VERSION ""

NS_ :

BS_:

BU_: BMS CanAnalyzer Charger ANY BMS CanAnalyzer Charger ANY

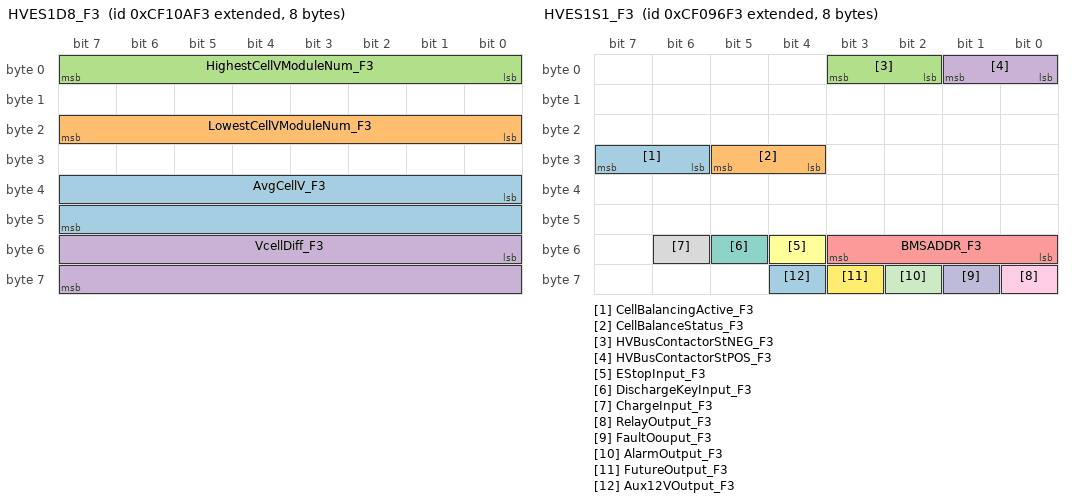
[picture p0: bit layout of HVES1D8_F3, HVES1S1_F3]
BO_ 2364607219 HVES1D8_F3: 8 BMS
 SG_ AvgCellV_F3 : 32|16@1+ (0.001,0) [0|65.535] "V"  CanAnalyzer
 SG_ LowestCellVModuleNum_F3 : 16|8@1+ (1,0) [0|250] ""  CanAnalyzer
 SG_ HighestCellVModuleNum_F3 : 0|8@1+ (1,0) [0|250] ""  CanAnalyzer
 SG_ VcellDiff_F3 : 48|16@1+ (0.001,0) [0|65.535] "V" Vector__XXX

BO_ 2364577523 HVES1S1_F3: 8 BMS
 SG_ CellBalancingActive_F3 : 30|2@1+ (1,0) [0|3] ""  CanAnalyzer
 SG_ CellBalanceStatus_F3 : 28|2@1+ (1,0) [0|3] ""  CanAnalyzer
 SG_ HVBusContactorStNEG_F3 : 2|2@1+ (1,0) [0|3] ""  CanAnalyzer
 SG_ HVBusContactorStPOS_F3 : 0|2@1+ (1,0) [0|3] ""  CanAnalyzer
 SG_ BMSADDR_F3 : 48|4@1+ (1,0) [0|1] "" Vector__XXX
 SG_ EStopInput_F3 : 52|1@1+ (1,0) [0|1] "" Vector__XXX
 SG_ DischargeKeyInput_F3 : 53|1@1+ (1,0) [0|1] "" Vector__XXX
 SG_ ChargeInput_F3 : 54|1@1+ (1,0) [0|1] "" Vector__XXX
 SG_ RelayOutput_F3 : 56|1@1+ (1,0) [0|1] "" Vector__XXX
 SG_ FaultOouput_F3 : 57|1@1+ (1,0) [0|1] "" Vector__XXX
 SG_ AlarmOutput_F3 : 58|1@1+ (1,0) [0|1] "" Vector__XXX
 SG_ FutureOutput_F3 : 59|1@1+ (1,0) [0|1] "" Vector__XXX
 SG_ Aux12VOutput_F3 : 60|1@1+ (1,0) [0|1] "" Vector__XXX

BO_ 2364577267 HVES1D6_F3: 8 BMS
 SG_ BusVoltage_F3 : 0|16@1+ (0.05,0) [0|65.535] "V"  CanAnalyzer

BO_ 2364576755 HVES1D4_F3: 8 BMS
 SG_ ChargeCapacity_01 : 16|16@1+ (0.01,0) [0|655.35] "Ah"  CanAnalyzer
 SG_ DischargeCapacity_01 : 0|16@1+ (0.01,0) [0|655.35] "Ah"  CanAnalyzer
 SG_ AvailableCapacity_01 : 48|16@1+ (0.01,0) [0|655.35] "Ah" Vector__XXX

BO_ 2350641993 HVES1C1_CF3: 8 ANY
 SG_ HVBusConnectCmd_cF3 : 0|2@1+ (1,0) [0|3] ""  CanAnalyzer
 SG_ BMSAddr_cF3 : 24|8@1+ (1,0) [101|114] "" Vector__XXX

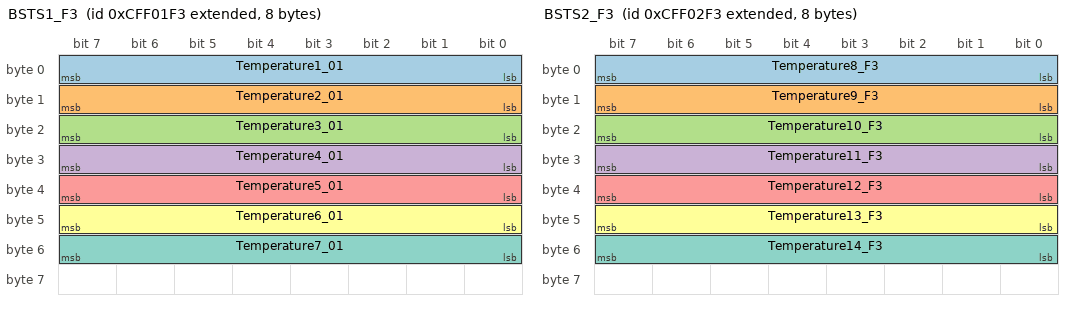
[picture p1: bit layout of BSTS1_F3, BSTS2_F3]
BO_ 2365522419 BSTS1_F3: 8 BMS
 SG_ Temperature1_01 : 0|8@1- (1,-40) [-40|210] "C"  CanAnalyzer
 SG_ Temperature2_01 : 8|8@1- (1,-40) [-40|210] "C"  CanAnalyzer
 SG_ Temperature3_01 : 16|8@1- (1,-40) [-40|210] "C"  CanAnalyzer
 SG_ Temperature4_01 : 24|8@1- (1,-40) [-40|210] "C"  CanAnalyzer
 SG_ Temperature5_01 : 32|8@1- (1,-40) [-40|210] "C"  CanAnalyzer
 SG_ Temperature6_01 : 40|8@1- (1,-40) [-40|210] "C"  CanAnalyzer
 SG_ Temperature7_01 : 48|8@1- (1,-40) [-40|210] "C"  CanAnalyzer

BO_ 2365522675 BSTS2_F3: 8 BMS
 SG_ Temperature8_F3 : 0|8@1- (1,-40) [-40|210] "C"  CanAnalyzer
 SG_ Temperature9_F3 : 8|8@1- (1,-40) [-40|210] "C"  CanAnalyzer
 SG_ Temperature10_F3 : 16|8@1- (1,-40) [-40|210] "C"  CanAnalyzer
 SG_ Temperature11_F3 : 24|8@1- (1,-40) [-40|210] "C"  CanAnalyzer
 SG_ Temperature12_F3 : 32|8@1- (1,-40) [-40|210] "C"  CanAnalyzer
 SG_ Temperature13_F3 : 40|8@1- (1,-40) [-40|210] "C"  CanAnalyzer
 SG_ Temperature14_F3 : 48|8@1- (1,-40) [-40|210] "C"  CanAnalyzer

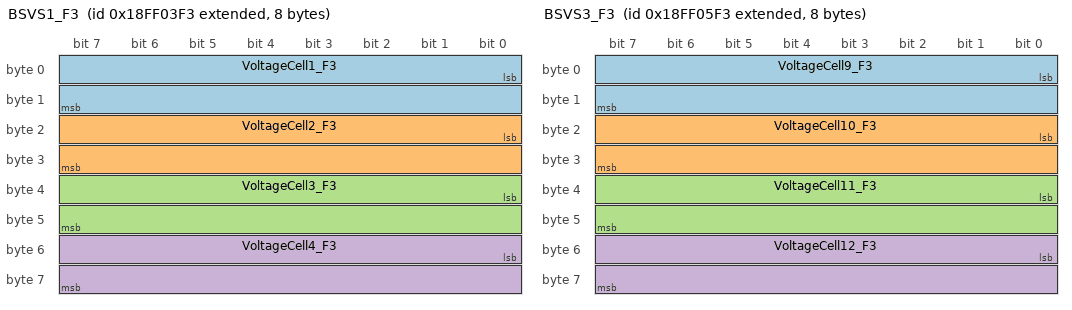
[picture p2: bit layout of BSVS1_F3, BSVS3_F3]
BO_ 2566849523 BSVS1_F3: 8 BMS
 SG_ VoltageCell1_F3 : 0|16@1+ (0.001,0) [0|65.535] "V"  CanAnalyzer
 SG_ VoltageCell2_F3 : 16|16@1+ (0.001,0) [0|65.535] "V"  CanAnalyzer
 SG_ VoltageCell3_F3 : 32|16@1+ (0.001,0) [0|65.535] "V"  CanAnalyzer
 SG_ VoltageCell4_F3 : 48|16@1+ (0.001,0) [0|65.535] "V"  CanAnalyzer

BO_ 2566850035 BSVS3_F3: 8 BMS
 SG_ VoltageCell9_F3 : 0|16@1+ (0.001,0) [0|65.535] "V"  CanAnalyzer
 SG_ VoltageCell10_F3 : 16|16@1+ (0.001,0) [0|65.535] "V"  CanAnalyzer
 SG_ VoltageCell11_F3 : 32|16@1+ (0.001,0) [0|65.535] "V"  CanAnalyzer
 SG_ VoltageCell12_F3 : 48|16@1+ (0.001,0) [0|65.535] "V"  CanAnalyzer

BO_ 2364575987 HVES1D1_F3: 8 BMS
 SG_ PackCurrentlvl_F3 : 48|16@1- (0.05,-1600) [-1600|1676.75] "A"  CanAnalyzer
 SG_ PackVoltagelvl_F3 : 32|16@1+ (0.05,0) [0|655.35] "V"  CanAnalyzer

BO_ 2365523699 SOC_F3: 8 BMS
 SG_ SoC_F3 : 0|16@1+ (1,0) [0|120] "%"  CanAnalyzer

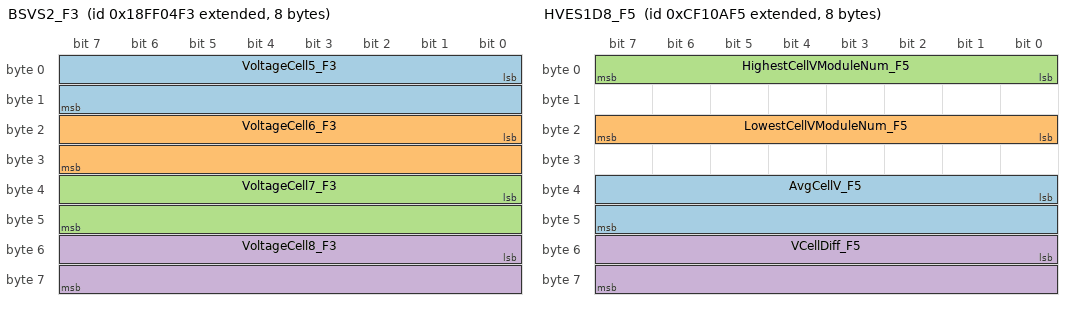
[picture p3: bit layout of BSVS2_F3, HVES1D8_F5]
BO_ 2566849779 BSVS2_F3: 8 BMS
 SG_ VoltageCell5_F3 : 0|16@1+ (0.001,0) [0|65.535] "V" Vector__XXX
 SG_ VoltageCell6_F3 : 16|16@1+ (0.001,0) [0|65.535] "V" Vector__XXX
 SG_ VoltageCell7_F3 : 32|16@1+ (0.001,0) [0|65.535] "V" Vector__XXX
 SG_ VoltageCell8_F3 : 48|16@1+ (0.001,0) [0|65.535] "V" Vector__XXX

BO_ 2566850291 BSVS4_F3: 8 BMS
 SG_ VoltageCell13_F3 : 0|16@1+ (0.001,0) [0|65.535] "V" Vector__XXX
 SG_ VoltageCell14_F3 : 16|16@1+ (0.001,0) [0|65.535] "V" Vector__XXX

BO_ 2364607221 HVES1D8_F5: 8 BMS
 SG_ AvgCellV_F5 : 32|16@1+ (0.001,0) [0|65.535] "V" Vector__XXX
 SG_ LowestCellVModuleNum_F5 : 16|8@1+ (1,0) [0|255] "" Vector__XXX
 SG_ HighestCellVModuleNum_F5 : 0|8@1+ (1,0) [0|255] "" Vector__XXX
 SG_ VCellDiff_F5 : 48|16@1+ (0.001,0) [0|65.535] "V" Vector__XXX

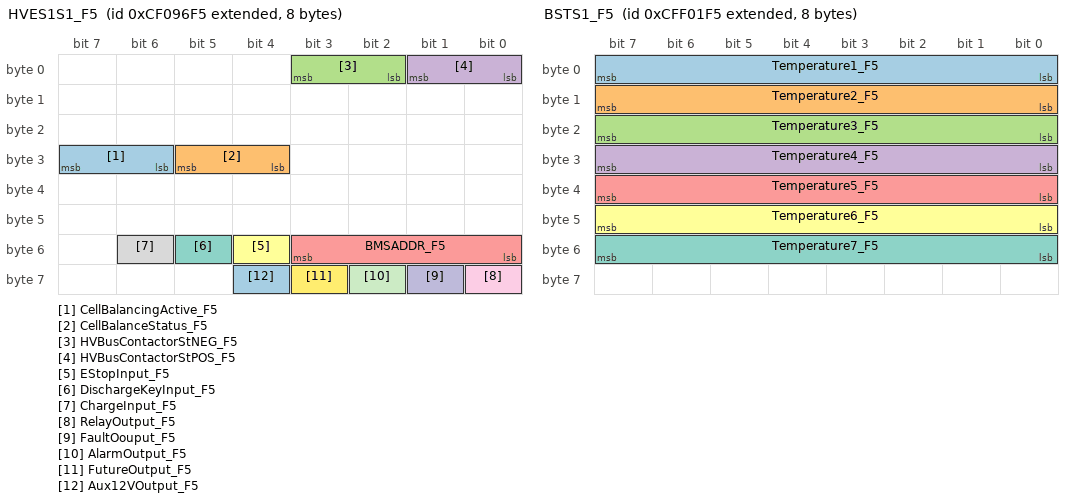
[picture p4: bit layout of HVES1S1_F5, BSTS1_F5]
BO_ 2364577525 HVES1S1_F5: 8 BMS
 SG_ CellBalancingActive_F5 : 30|2@1+ (1,0) [0|3] "" Vector__XXX
 SG_ CellBalanceStatus_F5 : 28|2@1+ (1,0) [0|3] "" Vector__XXX
 SG_ HVBusContactorStNEG_F5 : 2|2@1+ (1,0) [0|3] "" Vector__XXX
 SG_ HVBusContactorStPOS_F5 : 0|2@1+ (1,0) [0|3] "" Vector__XXX
 SG_ BMSADDR_F5 : 48|4@1+ (1,0) [0|15] "" Vector__XXX
 SG_ EStopInput_F5 : 52|1@1+ (1,0) [0|1] "" Vector__XXX
 SG_ DischargeKeyInput_F5 : 53|1@1+ (1,0) [0|1] "" Vector__XXX
 SG_ ChargeInput_F5 : 54|1@1+ (1,0) [0|1] "" Vector__XXX
 SG_ RelayOutput_F5 : 56|1@1+ (1,0) [0|1] "" Vector__XXX
 SG_ FaultOouput_F5 : 57|1@1+ (1,0) [0|1] "" Vector__XXX
 SG_ AlarmOutput_F5 : 58|1@1+ (1,0) [0|1] "" Vector__XXX
 SG_ FutureOutput_F5 : 59|1@1+ (1,0) [0|1] "" Vector__XXX
 SG_ Aux12VOutput_F5 : 60|1@1+ (1,0) [0|1] "" Vector__XXX

BO_ 2364577269 HVES1D6_F5: 8 BMS
 SG_ BusVoltage_F5 : 0|16@1+ (0.001,0) [0|6.5535] "V" Vector__XXX

BO_ 2364576757 HVES1D4_F5: 8 BMS
 SG_ ChargeCapacity_F5 : 16|16@1+ (0.01,0) [0|655.35] "Ah" Vector__XXX
 SG_ DischargeCapacity_F5 : 0|16@1+ (0.01,0) [0|655.35] "Ah" Vector__XXX
 SG_ AvailableCapacity_F5 : 32|32@1+ (0.01,0) [0|655.35] "Ah" Vector__XXX

BO_ 2365522421 BSTS1_F5: 8 BMS
 SG_ Temperature1_F5 : 0|8@1- (1,-40) [-40|210] "C" Vector__XXX
 SG_ Temperature2_F5 : 8|8@1- (1,-40) [-40|210] "C" Vector__XXX
 SG_ Temperature3_F5 : 16|8@1- (1,-40) [-40|210] "C" Vector__XXX
 SG_ Temperature4_F5 : 24|8@1- (1,-40) [-40|210] "C" Vector__XXX
 SG_ Temperature5_F5 : 32|8@1- (1,-40) [-40|210] "C" Vector__XXX
 SG_ Temperature6_F5 : 40|8@1- (1,-40) [-40|210] "C" Vector__XXX
 SG_ Temperature7_F5 : 48|8@1- (1,-40) [-40|210] "C" Vector__XXX

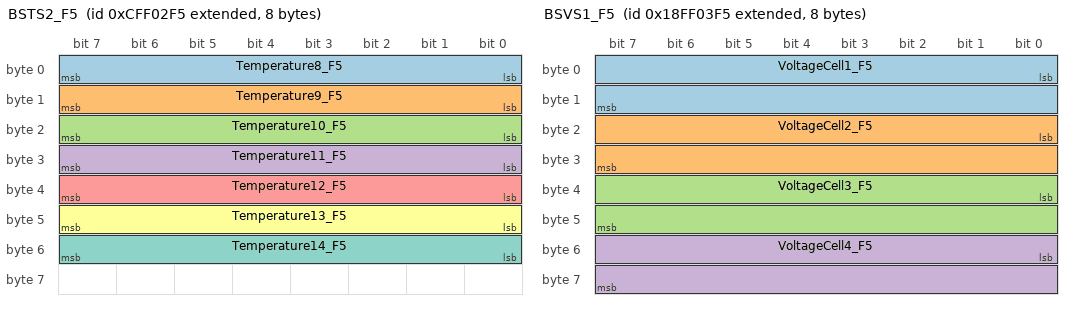
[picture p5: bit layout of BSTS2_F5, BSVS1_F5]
BO_ 2365522677 BSTS2_F5: 8 BMS
 SG_ Temperature8_F5 : 0|8@1- (1,-40) [-40|210] "C" Vector__XXX
 SG_ Temperature9_F5 : 8|8@1- (1,-40) [-40|210] "C" Vector__XXX
 SG_ Temperature10_F5 : 16|8@1- (1,-40) [-40|210] "C" Vector__XXX
 SG_ Temperature11_F5 : 24|8@1- (1,-40) [-40|210] "C" Vector__XXX
 SG_ Temperature12_F5 : 32|8@1- (1,-40) [-40|210] "C" Vector__XXX
 SG_ Temperature13_F5 : 40|8@1- (1,-40) [-40|210] "C" Vector__XXX
 SG_ Temperature14_F5 : 48|8@1- (1,-40) [-40|210] "C" Vector__XXX

BO_ 2566849525 BSVS1_F5: 8 BMS
 SG_ VoltageCell1_F5 : 0|16@1+ (0.001,0) [0|65.535] "V" Vector__XXX
 SG_ VoltageCell2_F5 : 16|16@1+ (0.001,0) [0|65.535] "V" Vector__XXX
 SG_ VoltageCell3_F5 : 32|16@1+ (0.001,0) [0|65.535] "V" Vector__XXX
 SG_ VoltageCell4_F5 : 48|16@1+ (0.001,0) [0|65.535] "V" Vector__XXX

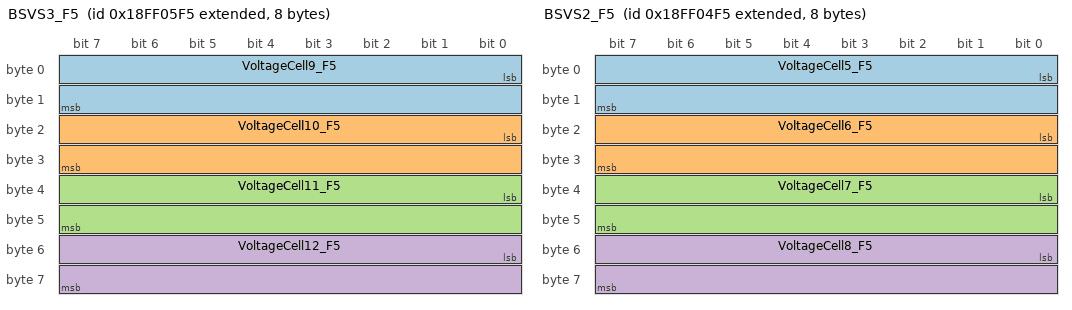
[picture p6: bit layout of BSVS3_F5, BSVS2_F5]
BO_ 2566850037 BSVS3_F5: 8 BMS
 SG_ VoltageCell9_F5 : 0|16@1+ (0.001,0) [0|65.535] "V" Vector__XXX
 SG_ VoltageCell10_F5 : 16|16@1+ (0.001,0) [0|65.535] "V" Vector__XXX
 SG_ VoltageCell11_F5 : 32|16@1+ (0.001,0) [0|65.535] "V" Vector__XXX
 SG_ VoltageCell12_F5 : 48|16@1+ (0.001,0) [0|65.535] "V" Vector__XXX

BO_ 2364575989 HVES1D1_F5: 8 BMS
 SG_ PackCurrentlvl_F5 : 48|16@1- (0.05,-1600) [0|1676.75] "A" Vector__XXX
 SG_ PackVoltagelvl_F5 : 32|16@1+ (0.05,0) [0|655.35] "V" Vector__XXX

BO_ 2365523701 SOC_F5: 8 BMS
 SG_ SoC_F5 : 0|16@1+ (1,0) [0|120] "%" Vector__XXX

BO_ 2566849781 BSVS2_F5: 8 BMS
 SG_ VoltageCell5_F5 : 0|16@1+ (0.001,0) [0|65.535] "V" Vector__XXX
 SG_ VoltageCell6_F5 : 16|16@1+ (0.001,0) [0|65.535] "V" Vector__XXX
 SG_ VoltageCell7_F5 : 32|16@1+ (0.001,0) [0|65.535] "V" Vector__XXX
 SG_ VoltageCell8_F5 : 48|16@1+ (0.001,0) [0|65.535] "V" Vector__XXX

BO_ 2566850293 BSVS4_F5: 8 BMS
 SG_ VoltageCell13_F5 : 0|16@1+ (0.001,0) [0|65.535] "V" Vector__XXX
 SG_ VoltageCell14_F5 : 16|16@1+ (0.001,0) [0|65.535] "V" Vector__XXX

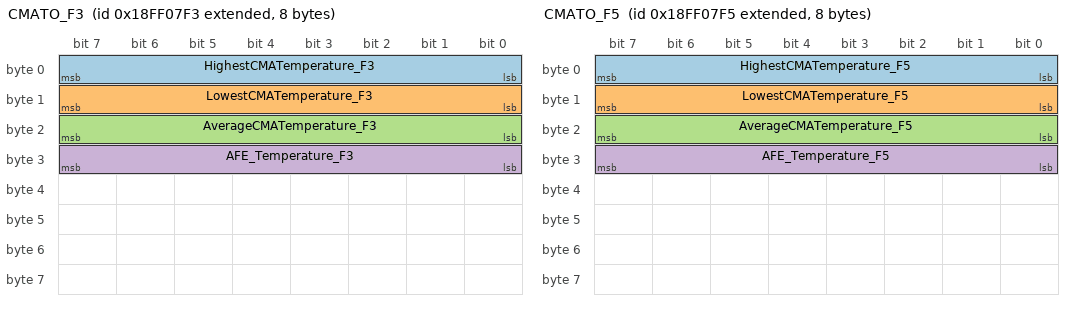
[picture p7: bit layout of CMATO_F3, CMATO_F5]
BO_ 2566850547 CMATO_F3: 8 BMS
 SG_ HighestCMATemperature_F3 : 0|8@1- (1,-40) [-40|210] "C" Vector__XXX
 SG_ LowestCMATemperature_F3 : 8|8@1- (1,-40) [-40|210] "C" Vector__XXX
 SG_ AverageCMATemperature_F3 : 16|8@1- (1,-40) [-40|210] "C" Vector__XXX
 SG_ AFE_Temperature_F3 : 24|8@1- (1,-40) [-40|210] "C" Vector__XXX

BO_ 2566850549 CMATO_F5: 8 BMS
 SG_ HighestCMATemperature_F5 : 0|8@1- (1,-40) [-40|210] "C" Vector__XXX
 SG_ LowestCMATemperature_F5 : 8|8@1- (1,-40) [-40|210] "C" Vector__XXX
 SG_ AverageCMATemperature_F5 : 16|8@1- (1,-40) [-40|210] "C" Vector__XXX
 SG_ AFE_Temperature_F5 : 24|8@1- (1,-40) [-40|210] "C" Vector__XXX

BO_ 2566850803 STATUS_F3: 8 BMS
 SG_ CommMode_F3 : 0|1@1+ (1,0) [0|1] "" Vector__XXX
 SG_ DischargeMode_F3 : 1|1@1+ (1,0) [0|1] "" Vector__XXX
 SG_ ChargeMode_F3 : 2|1@1+ (1,0) [0|1] "" Vector__XXX
 SG_ BSDCMDMode_F3 : 3|1@1+ (1,0) [0|1] "" Vector__XXX
 SG_ ReadyStatus_F3 : 8|1@1+ (1,0) [0|1] "" Vector__XXX
 SG_ NormalStatus_F3 : 9|1@1+ (1,0) [0|1] "" Vector__XXX
 SG_ FinishStatus_F3 : 10|1@1+ (1,0) [0|1] "" Vector__XXX
 SG_ ProtectStatus_F3 : 11|1@1+ (1,0) [0|1] "" Vector__XXX
 SG_ LowVoltageProtect_F3 : 16|1@1+ (1,0) [0|1] "" Vector__XXX
 SG_ TemperatureProtect_F3 : 17|1@1+ (1,0) [0|1] "" Vector__XXX
 SG_ CurrentProtect_F3 : 18|1@1+ (1,0) [0|1] "" Vector__XXX
 SG_ ZeroCurrentProtect_F3 : 19|1@1+ (1,0) [0|1] "" Vector__XXX
 SG_ OverVoltageProtect_F3 : 20|1@1+ (1,0) [0|1] "" Vector__XXX
 SG_ MaintenProtect_F3 : 21|1@1+ (1,0) [0|1] "" Vector__XXX
 SG_ BalanceProtect_F3 : 22|1@1+ (1,0) [0|1] "" Vector__XXX
 SG_ ChargerNotMatchProtect_F3 : 23|1@1+ (1,0) [0|1] "" Vector__XXX
 SG_ NoCanMsgEnableProtect_F3 : 24|1@1+ (1,0) [0|1] "" Vector__XXX
 SG_ ContactorIssueProtect_F3 : 25|1@1+ (1,0) [0|1] "" Vector__XXX
 SG_ EStopProtect_F3 : 26|1@1+ (1,0) [0|1] "" Vector__XXX
 SG_ StartVoltProtect_F3 : 27|1@1+ (1,0) [0|1] "" Vector__XXX
 SG_ BMSAddrChangedProtect_F3 : 30|1@1+ (1,0) [0|1] "" Vector__XXX
 SG_ PermanentFaultProtect_F3 : 31|1@1+ (1,0) [0|1] "" Vector__XXX
 SG_ LowVoltageAlarm_F3 : 32|1@1+ (1,0) [0|1] "" Vector__XXX
 SG_ TemperatureAlarm_F3 : 33|1@1+ (1,0) [0|1] "" Vector__XXX
 SG_ CurrentAlarm_F3 : 34|1@1+ (1,0) [0|1] "" Vector__XXX
 SG_ ZeroCurrentAlarm_F3 : 35|1@1+ (1,0) [0|1] "" Vector__XXX
 SG_ OverVoltAlarm_F3 : 36|1@1+ (1,0) [0|1] "" Vector__XXX
 SG_ MaintenaceAlarm_F3 : 37|1@1+ (1,0) [0|1] "" Vector__XXX
 SG_ BalanaceAlarm_F3 : 38|1@1+ (1,0) [0|1] "" Vector__XXX
 SG_ ChargerNotMatchAlarm_F3 : 39|1@1+ (1,0) [0|1] "" Vector__XXX
 SG_ CanMsgAlarm_F3 : 40|1@1+ (1,0) [0|1] "" Vector__XXX
 SG_ ContactorAlarm_F3 : 41|1@1+ (1,0) [0|1] "" Vector__XXX
 SG_ EstopAlarm_F3 : 42|1@1+ (1,0) [0|1] "" Vector__XXX
 SG_ StartVoltAlarm_F3 : 43|1@1+ (1,0) [0|1] "" Vector__XXX
 SG_ BMSMultipleAddressFault_F3 : 48|8@1+ (1,0) [0|255] "" Vector__XXX
 SG_ BSDCFGMODE_F3 : 4|1@1+ (1,0) [0|1] "" Vector__XXX
 SG_ AFECommAlarm_F3 : 44|1@1+ (1,0) [0|1] "" Vector__XXX
 SG_ BusVoltageMatchAlarm_F3 : 45|1@1+ (1,0) [0|1] "" Vector__XXX
 SG_ ChargerStatu_F3 : 56|8@1+ (1,0) [0|255] "" Vector__XXX

BO_ 2566850805 STATUS_F5: 8 BMS
 SG_ CommMode_F5 : 0|1@1+ (1,0) [0|1] "" Vector__XXX
 SG_ DischargeMode_F5 : 1|1@1+ (1,0) [0|1] "" Vector__XXX
 SG_ ChargeMode_F5 : 2|1@1+ (1,0) [0|1] "" Vector__XXX
 SG_ BSDCMDMode_F5 : 3|1@1+ (1,0) [0|1] "" Vector__XXX
 SG_ ReadyStatus_F5 : 8|1@1+ (1,0) [0|1] "" Vector__XXX
 SG_ NormalStatus_F5 : 9|1@1+ (1,0) [0|1] "" Vector__XXX
 SG_ FinishStatus_F5 : 10|1@1+ (1,0) [0|1] "" Vector__XXX
 SG_ ProtectStatus_F5 : 11|1@1+ (1,0) [0|1] "" Vector__XXX
 SG_ LowVoltageProtect_F5 : 16|1@1+ (1,0) [0|1] "" Vector__XXX
 SG_ TemperatureProtect_F5 : 17|1@1+ (1,0) [0|1] "" Vector__XXX
 SG_ CurrentProtect__F5 : 18|1@1+ (1,0) [0|1] "" Vector__XXX
 SG_ ZeroCurrentProtect_F5 : 19|1@1+ (1,0) [0|1] "" Vector__XXX
 SG_ OverVoltageProtect__F5 : 20|1@1+ (1,0) [0|1] "" Vector__XXX
 SG_ MaintenProtect_F5 : 21|1@1+ (1,0) [0|1] "" Vector__XXX
 SG_ BalanceProtect_F5 : 22|1@1+ (1,0) [0|1] "" Vector__XXX
 SG_ ChargerNotMatchProtect_F5 : 23|1@1+ (1,0) [0|1] "" Vector__XXX
 SG_ NoCanMsgEnableProtect_F5 : 24|1@1+ (1,0) [0|1] "" Vector__XXX
 SG_ ContactorIssueProtect_F5 : 25|1@1+ (1,0) [0|1] "" Vector__XXX
 SG_ EStopProtect_F5 : 26|1@1+ (1,0) [0|1] "" Vector__XXX
 SG_ StartVoltProtect_F5 : 27|1@1+ (1,0) [0|1] "" Vector__XXX
 SG_ BMSAddrChangedProtect_F5 : 30|1@1+ (1,0) [0|1] "" Vector__XXX
 SG_ PermanentFaultProtect_F5 : 31|1@1+ (1,0) [0|1] "" Vector__XXX
 SG_ LowVoltageAlarm_F5 : 32|1@1+ (1,0) [0|1] "" Vector__XXX
 SG_ TemperatureAlarm_F5 : 33|1@1+ (1,0) [0|1] "" Vector__XXX
 SG_ CurrentAlarm_F5 : 34|1@1+ (1,0) [0|1] "" Vector__XXX
 SG_ ZeroCurrentAlarm_F5 : 35|1@1+ (1,0) [0|1] "" Vector__XXX
 SG_ OverVoltAlarm_F5 : 36|1@1+ (1,0) [0|1] "" Vector__XXX
 SG_ MaintenaceAlarm_F5 : 37|1@1+ (1,0) [0|1] "" Vector__XXX
 SG_ BalanaceAlarm_F5 : 38|1@1+ (1,0) [0|1] "" Vector__XXX
 SG_ ChargerNotMatchAlarm_F5 : 39|1@1+ (1,0) [0|1] "" Vector__XXX
 SG_ CanMsgAlarm_F5 : 40|1@1+ (1,0) [0|1] "" Vector__XXX
 SG_ ContactorAlarm_F5 : 41|1@1+ (1,0) [0|1] "" Vector__XXX
 SG_ EstopAlarm_F5 : 42|1@1+ (1,0) [0|1] "" Vector__XXX
 SG_ StartVoltAlarm_F5 : 43|1@1+ (1,0) [0|1] "" Vector__XXX
 SG_ BMSMultipleAddressFault_F5 : 48|8@1+ (1,0) [0|255] "" Vector__XXX
 SG_ BSDCFGMODE_F5 : 4|1@1+ (1,0) [0|1] "" Vector__XXX
 SG_ ChargerStatu_F5 : 56|8@1+ (1,0) [0|255] "" Vector__XXX

BO_ 2566861043 Version_F3: 8 BMS
 SG_ PCBAVersionDate_F3 : 0|24@1+ (1,0) [0|20990000] "" Vector__XXX
 SG_ SchVersionDate_F3 : 24|24@1+ (1,0) [0|16777200] "" Vector__XXX
 SG_ SoftwareVersion_F3 : 48|16@1+ (1,0) [0|65536] "" Vector__XXX

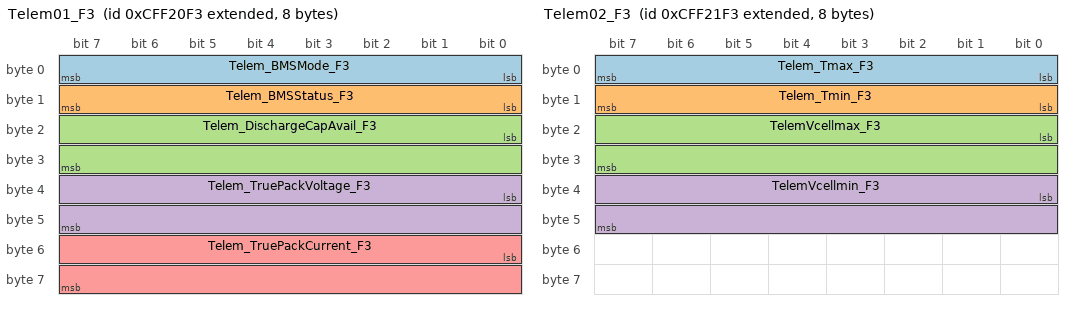
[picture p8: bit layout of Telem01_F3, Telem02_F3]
BO_ 2365530355 Telem01_F3: 8 BMS
 SG_ Telem_BMSMode_F3 : 0|8@1+ (1,0) [0|255] "" Vector__XXX
 SG_ Telem_BMSStatus_F3 : 8|8@1+ (1,0) [0|255] "" Vector__XXX
 SG_ Telem_DischargeCapAvail_F3 : 16|16@1+ (0.01,0) [0|655.35] "Ah" Vector__XXX
 SG_ Telem_TruePackVoltage_F3 : 32|16@1+ (0.001,0) [0|65.535] "V" Vector__XXX
 SG_ Telem_TruePackCurrent_F3 : 48|16@1+ (0.05,-1600) [-1600|1676.75] "A" Vector__XXX

BO_ 2365530611 Telem02_F3: 8 BMS
 SG_ Telem_Tmax_F3 : 0|8@1+ (1,-40) [-40|210] "C" Vector__XXX
 SG_ Telem_Tmin_F3 : 8|8@1+ (1,-40) [-40|210] "C" Vector__XXX
 SG_ TelemVcellmax_F3 : 16|16@1+ (0.001,0) [0|65.535] "V" Vector__XXX
 SG_ TelemVcellmin_F3 : 32|16@1+ (0.001,0) [0|65.535] "V" Vector__XXX

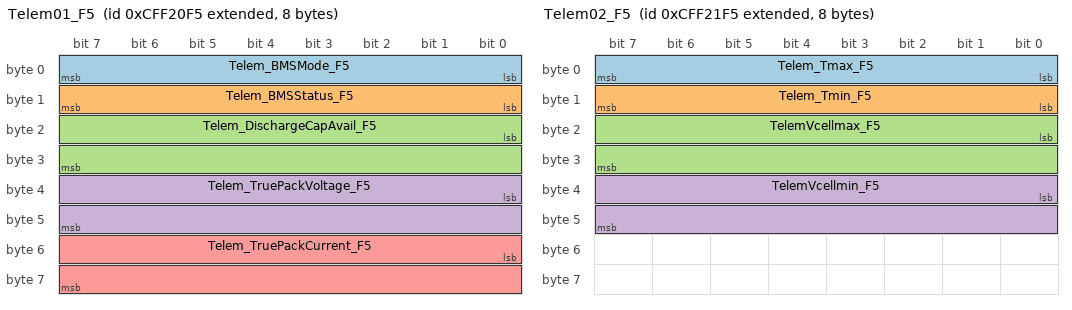
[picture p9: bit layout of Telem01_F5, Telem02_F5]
BO_ 2365530357 Telem01_F5: 8 BMS
 SG_ Telem_BMSMode_F5 : 0|8@1+ (1,0) [0|255] "" Vector__XXX
 SG_ Telem_BMSStatus_F5 : 8|8@1+ (1,0) [0|255] "" Vector__XXX
 SG_ Telem_DischargeCapAvail_F5 : 16|16@1+ (0.01,0) [0|655.35] "Ah" Vector__XXX
 SG_ Telem_TruePackVoltage_F5 : 32|16@1+ (0.001,0) [0|65.535] "V" Vector__XXX
 SG_ Telem_TruePackCurrent_F5 : 48|16@1+ (0.05,-1600) [-1600|1676.75] "A" Vector__XXX

BO_ 2365530613 Telem02_F5: 8 BMS
 SG_ Telem_Tmax_F5 : 0|8@1+ (1,-40) [-40|210] "C" Vector__XXX
 SG_ Telem_Tmin_F5 : 8|8@1+ (1,-40) [-40|210] "C" Vector__XXX
 SG_ TelemVcellmax_F5 : 16|16@1+ (0.001,0) [0|65.535] "V" Vector__XXX
 SG_ TelemVcellmin_F5 : 32|16@1+ (0.001,0) [0|65.535] "V" Vector__XXX

BO_ 2566861045 Version_F5: 8 BMS
 SG_ PCBAVersionDate_F5 : 0|24@1+ (1,0) [0|20990000] "" Vector__XXX
 SG_ SchVersionDate_F5 : 24|24@1+ (1,0) [0|16777200] "" Vector__XXX
 SG_ SoftwareVersion_F5 : 48|16@1+ (1,0) [0|65536] "" Vector__XXX

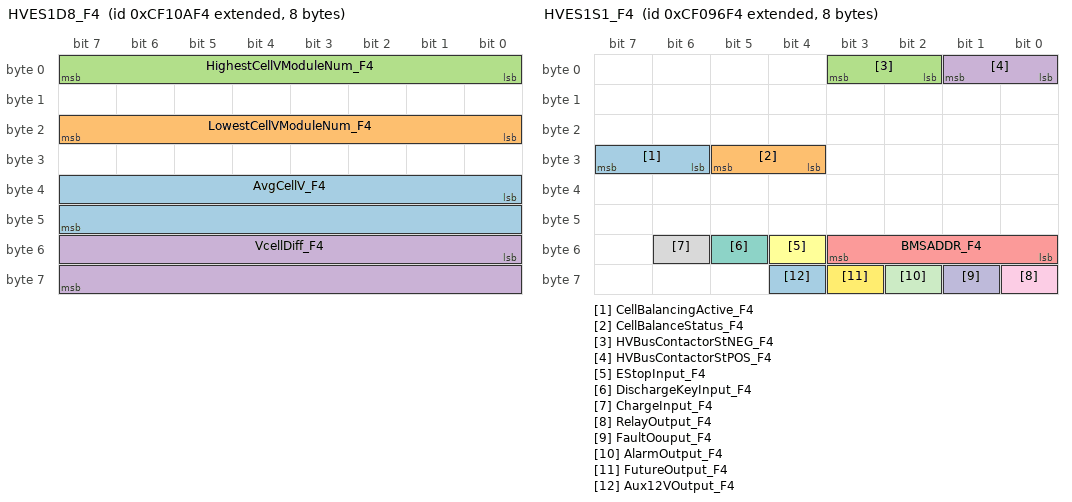
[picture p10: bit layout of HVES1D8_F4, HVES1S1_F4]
BO_ 2364607220 HVES1D8_F4: 8 BMS
 SG_ AvgCellV_F4 : 32|16@1+ (0.001,0) [0|65.535] "V"  CanAnalyzer
 SG_ LowestCellVModuleNum_F4 : 16|8@1+ (1,0) [0|250] ""  CanAnalyzer
 SG_ HighestCellVModuleNum_F4 : 0|8@1+ (1,0) [0|250] ""  CanAnalyzer
 SG_ VcellDiff_F4 : 48|16@1+ (0.001,0) [0|65.535] "V" Vector__XXX

BO_ 2364577524 HVES1S1_F4: 8 BMS
 SG_ CellBalancingActive_F4 : 30|2@1+ (1,0) [0|3] ""  CanAnalyzer
 SG_ CellBalanceStatus_F4 : 28|2@1+ (1,0) [0|3] ""  CanAnalyzer
 SG_ HVBusContactorStNEG_F4 : 2|2@1+ (1,0) [0|3] ""  CanAnalyzer
 SG_ HVBusContactorStPOS_F4 : 0|2@1+ (1,0) [0|3] ""  CanAnalyzer
 SG_ BMSADDR_F4 : 48|4@1+ (1,0) [0|1] "" Vector__XXX
 SG_ EStopInput_F4 : 52|1@1+ (1,0) [0|1] "" Vector__XXX
 SG_ DischargeKeyInput_F4 : 53|1@1+ (1,0) [0|1] "" Vector__XXX
 SG_ ChargeInput_F4 : 54|1@1+ (1,0) [0|1] "" Vector__XXX
 SG_ RelayOutput_F4 : 56|1@1+ (1,0) [0|1] "" Vector__XXX
 SG_ FaultOouput_F4 : 57|1@1+ (1,0) [0|1] "" Vector__XXX
 SG_ AlarmOutput_F4 : 58|1@1+ (1,0) [0|1] "" Vector__XXX
 SG_ FutureOutput_F4 : 59|1@1+ (1,0) [0|1] "" Vector__XXX
 SG_ Aux12VOutput_F4 : 60|1@1+ (1,0) [0|1] "" Vector__XXX

BO_ 2364577268 HVES1D6_F4: 8 BMS
 SG_ BusVoltage_F4 : 0|16@1+ (0.05,0) [0|65.535] "V"  CanAnalyzer

BO_ 2364576756 HVES1D4_F4: 8 BMS
 SG_ ChargeCapacity_F4 : 16|16@1+ (0.01,0) [0|655.35] "Ah"  CanAnalyzer
 SG_ DischargeCapacity_F4 : 0|16@1+ (0.01,0) [0|655.35] "Ah"  CanAnalyzer
 SG_ AvailableCapacity_F4 : 48|16@1+ (0.01,0) [0|655.35] "Ah" Vector__XXX

BO_ 2350642249 HVES1C1_CF4: 8 ANY
 SG_ HVBusConnectCmd_cF4 : 0|2@1+ (1,0) [0|3] ""  CanAnalyzer
 SG_ BMSAddr_cF4 : 24|8@1+ (1,0) [101|114] "" Vector__XXX

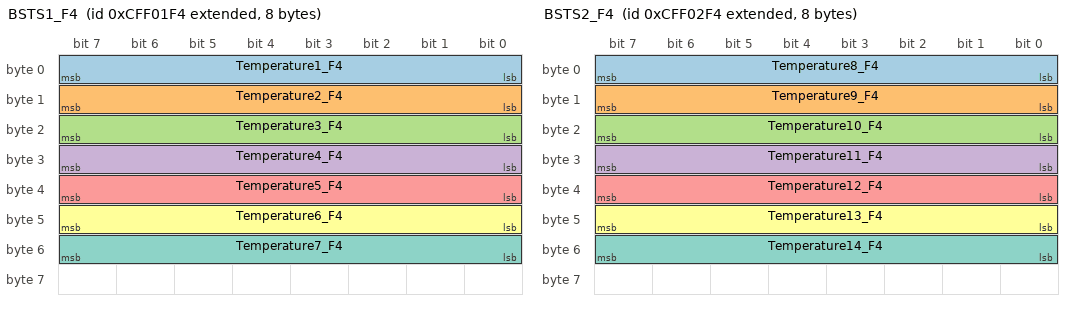
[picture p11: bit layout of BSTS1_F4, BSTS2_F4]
BO_ 2365522420 BSTS1_F4: 8 BMS
 SG_ Temperature1_F4 : 0|8@1- (1,-40) [-40|210] "C"  CanAnalyzer
 SG_ Temperature2_F4 : 8|8@1- (1,-40) [-40|210] "C"  CanAnalyzer
 SG_ Temperature3_F4 : 16|8@1- (1,-40) [-40|210] "C"  CanAnalyzer
 SG_ Temperature4_F4 : 24|8@1- (1,-40) [-40|210] "C"  CanAnalyzer
 SG_ Temperature5_F4 : 32|8@1- (1,-40) [-40|210] "C"  CanAnalyzer
 SG_ Temperature6_F4 : 40|8@1- (1,-40) [-40|210] "C"  CanAnalyzer
 SG_ Temperature7_F4 : 48|8@1- (1,-40) [-40|210] "C"  CanAnalyzer

BO_ 2365522676 BSTS2_F4: 8 BMS
 SG_ Temperature8_F4 : 0|8@1- (1,-40) [-40|210] "C"  CanAnalyzer
 SG_ Temperature9_F4 : 8|8@1- (1,-40) [-40|210] "C"  CanAnalyzer
 SG_ Temperature10_F4 : 16|8@1- (1,-40) [-40|210] "C"  CanAnalyzer
 SG_ Temperature11_F4 : 24|8@1- (1,-40) [-40|210] "C"  CanAnalyzer
 SG_ Temperature12_F4 : 32|8@1- (1,-40) [-40|210] "C"  CanAnalyzer
 SG_ Temperature13_F4 : 40|8@1- (1,-40) [-40|210] "C"  CanAnalyzer
 SG_ Temperature14_F4 : 48|8@1- (1,-40) [-40|210] "C"  CanAnalyzer

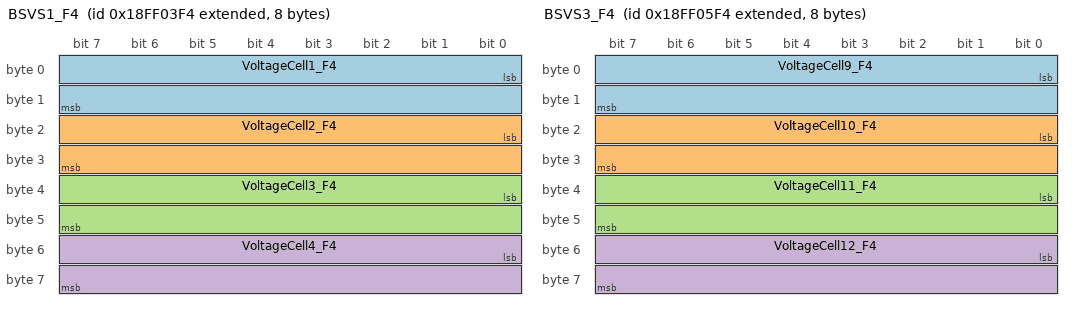
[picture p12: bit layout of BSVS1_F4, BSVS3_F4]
BO_ 2566849524 BSVS1_F4: 8 BMS
 SG_ VoltageCell1_F4 : 0|16@1+ (0.001,0) [0|65.535] "V"  CanAnalyzer
 SG_ VoltageCell2_F4 : 16|16@1+ (0.001,0) [0|65.535] "V"  CanAnalyzer
 SG_ VoltageCell3_F4 : 32|16@1+ (0.001,0) [0|65.535] "V"  CanAnalyzer
 SG_ VoltageCell4_F4 : 48|16@1+ (0.001,0) [0|65.535] "V"  CanAnalyzer

BO_ 2566850036 BSVS3_F4: 8 BMS
 SG_ VoltageCell9_F4 : 0|16@1+ (0.001,0) [0|65.535] "V"  CanAnalyzer
 SG_ VoltageCell10_F4 : 16|16@1+ (0.001,0) [0|65.535] "V"  CanAnalyzer
 SG_ VoltageCell11_F4 : 32|16@1+ (0.001,0) [0|65.535] "V"  CanAnalyzer
 SG_ VoltageCell12_F4 : 48|16@1+ (0.001,0) [0|65.535] "V"  CanAnalyzer

BO_ 2364575988 HVES1D1_F4: 8 BMS
 SG_ PackCurrentlvl_F4 : 48|16@1- (0.05,-1600) [-1600|1676.75] "A"  CanAnalyzer
 SG_ PackVoltagelvl_F4 : 32|16@1+ (0.05,0) [0|655.35] "V"  CanAnalyzer

BO_ 2365523700 SOC_F4: 8 BMS
 SG_ SoC_F4 : 0|16@1+ (1,0) [0|120] "%"  CanAnalyzer

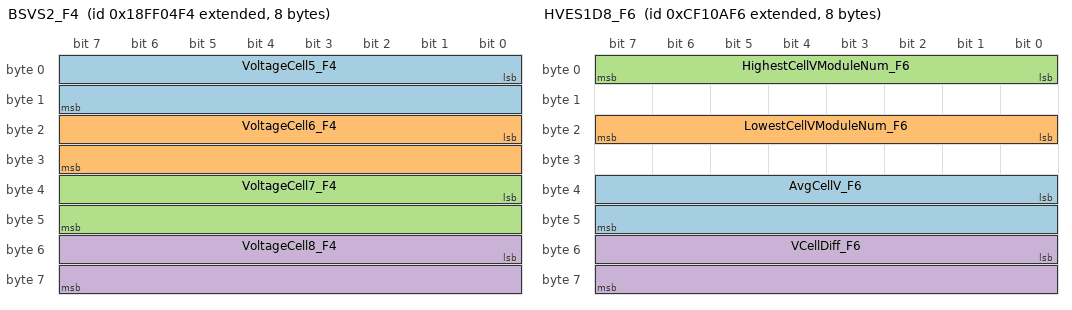
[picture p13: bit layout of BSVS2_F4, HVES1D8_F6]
BO_ 2566849780 BSVS2_F4: 8 BMS
 SG_ VoltageCell5_F4 : 0|16@1+ (0.001,0) [0|65.535] "V" Vector__XXX
 SG_ VoltageCell6_F4 : 16|16@1+ (0.001,0) [0|65.535] "V" Vector__XXX
 SG_ VoltageCell7_F4 : 32|16@1+ (0.001,0) [0|65.535] "V" Vector__XXX
 SG_ VoltageCell8_F4 : 48|16@1+ (0.001,0) [0|65.535] "V" Vector__XXX

BO_ 2566850292 BSVS4_F4: 8 BMS
 SG_ VoltageCell13_F4 : 0|16@1+ (0.001,0) [0|65.535] "V" Vector__XXX
 SG_ VoltageCell14_F4 : 16|16@1+ (0.001,0) [0|65.535] "V" Vector__XXX

BO_ 2364607222 HVES1D8_F6: 8 BMS
 SG_ AvgCellV_F6 : 32|16@1+ (0.001,0) [0|65.535] "V" Vector__XXX
 SG_ LowestCellVModuleNum_F6 : 16|8@1+ (1,0) [0|255] "" Vector__XXX
 SG_ HighestCellVModuleNum_F6 : 0|8@1+ (1,0) [0|255] "" Vector__XXX
 SG_ VCellDiff_F6 : 48|16@1+ (0.001,0) [0|65.535] "V" Vector__XXX

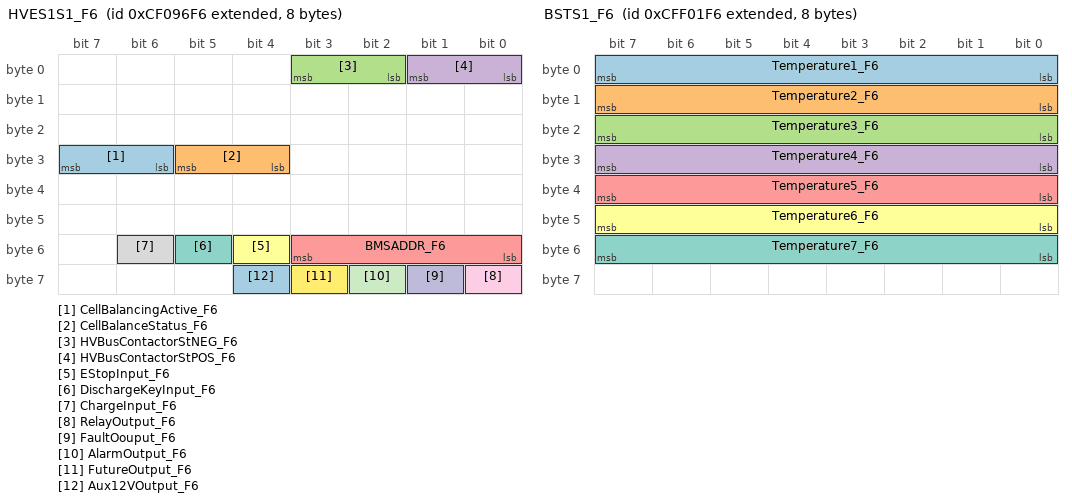
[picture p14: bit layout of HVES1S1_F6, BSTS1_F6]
BO_ 2364577526 HVES1S1_F6: 8 BMS
 SG_ CellBalancingActive_F6 : 30|2@1+ (1,0) [0|3] "" Vector__XXX
 SG_ CellBalanceStatus_F6 : 28|2@1+ (1,0) [0|3] "" Vector__XXX
 SG_ HVBusContactorStNEG_F6 : 2|2@1+ (1,0) [0|3] "" Vector__XXX
 SG_ HVBusContactorStPOS_F6 : 0|2@1+ (1,0) [0|3] "" Vector__XXX
 SG_ BMSADDR_F6 : 48|4@1+ (1,0) [0|15] "" Vector__XXX
 SG_ EStopInput_F6 : 52|1@1+ (1,0) [0|1] "" Vector__XXX
 SG_ DischargeKeyInput_F6 : 53|1@1+ (1,0) [0|1] "" Vector__XXX
 SG_ ChargeInput_F6 : 54|1@1+ (1,0) [0|1] "" Vector__XXX
 SG_ RelayOutput_F6 : 56|1@1+ (1,0) [0|1] "" Vector__XXX
 SG_ FaultOouput_F6 : 57|1@1+ (1,0) [0|1] "" Vector__XXX
 SG_ AlarmOutput_F6 : 58|1@1+ (1,0) [0|1] "" Vector__XXX
 SG_ FutureOutput_F6 : 59|1@1+ (1,0) [0|1] "" Vector__XXX
 SG_ Aux12VOutput_F6 : 60|1@1+ (1,0) [0|1] "" Vector__XXX

BO_ 2364577270 HVES1D6_F6: 8 BMS
 SG_ BusVoltage_F6 : 0|16@1+ (0.001,0) [0|6.5535] "V" Vector__XXX

BO_ 2364576758 HVES1D4_F6: 8 BMS
 SG_ ChargeCapacity_F6 : 16|16@1+ (0.01,0) [0|655.35] "Ah" Vector__XXX
 SG_ DischargeCapacity_F6 : 0|16@1+ (0.01,0) [0|655.35] "Ah" Vector__XXX
 SG_ AvailableCapacity_F6 : 32|32@1+ (0.01,0) [0|655.35] "Ah" Vector__XXX

BO_ 2365522422 BSTS1_F6: 8 BMS
 SG_ Temperature1_F6 : 0|8@1- (1,-40) [-40|210] "C" Vector__XXX
 SG_ Temperature2_F6 : 8|8@1- (1,-40) [-40|210] "C" Vector__XXX
 SG_ Temperature3_F6 : 16|8@1- (1,-40) [-40|210] "C" Vector__XXX
 SG_ Temperature4_F6 : 24|8@1- (1,-40) [-40|210] "C" Vector__XXX
 SG_ Temperature5_F6 : 32|8@1- (1,-40) [-40|210] "C" Vector__XXX
 SG_ Temperature6_F6 : 40|8@1- (1,-40) [-40|210] "C" Vector__XXX
 SG_ Temperature7_F6 : 48|8@1- (1,-40) [-40|210] "C" Vector__XXX

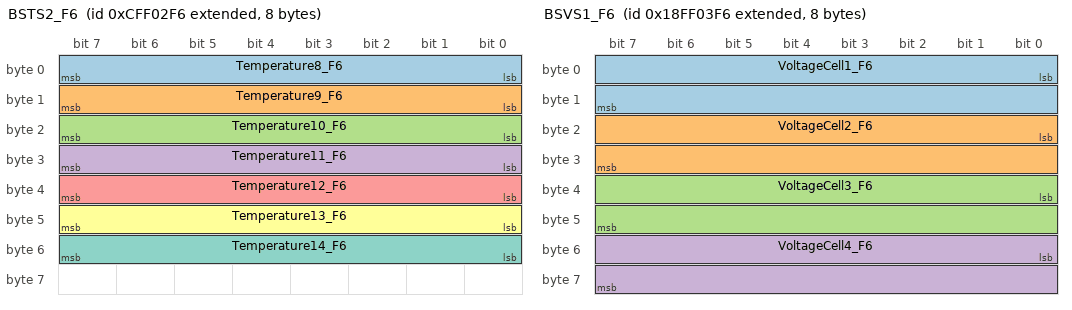
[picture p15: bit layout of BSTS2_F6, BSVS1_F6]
BO_ 2365522678 BSTS2_F6: 8 BMS
 SG_ Temperature8_F6 : 0|8@1- (1,-40) [-40|210] "C" Vector__XXX
 SG_ Temperature9_F6 : 8|8@1- (1,-40) [-40|210] "C" Vector__XXX
 SG_ Temperature10_F6 : 16|8@1- (1,-40) [-40|210] "C" Vector__XXX
 SG_ Temperature11_F6 : 24|8@1- (1,-40) [-40|210] "C" Vector__XXX
 SG_ Temperature12_F6 : 32|8@1- (1,-40) [-40|210] "C" Vector__XXX
 SG_ Temperature13_F6 : 40|8@1- (1,-40) [-40|210] "C" Vector__XXX
 SG_ Temperature14_F6 : 48|8@1- (1,-40) [-40|210] "C" Vector__XXX

BO_ 2566849526 BSVS1_F6: 8 BMS
 SG_ VoltageCell1_F6 : 0|16@1+ (0.001,0) [0|65.535] "V" Vector__XXX
 SG_ VoltageCell2_F6 : 16|16@1+ (0.001,0) [0|65.535] "V" Vector__XXX
 SG_ VoltageCell3_F6 : 32|16@1+ (0.001,0) [0|65.535] "V" Vector__XXX
 SG_ VoltageCell4_F6 : 48|16@1+ (0.001,0) [0|65.535] "V" Vector__XXX

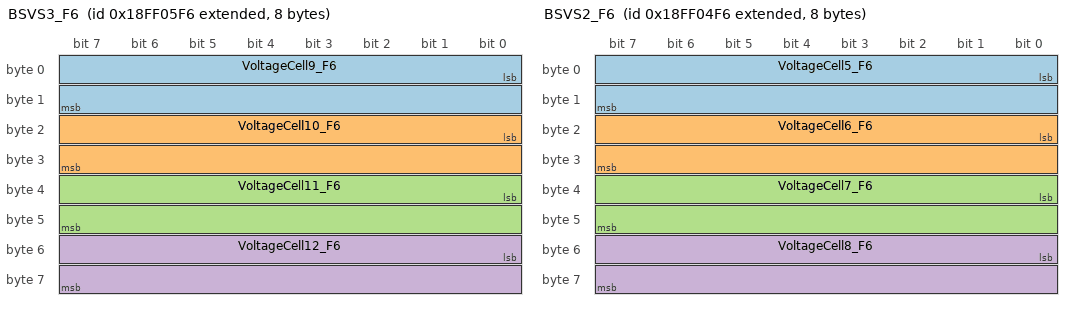
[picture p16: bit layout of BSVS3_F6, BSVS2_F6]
BO_ 2566850038 BSVS3_F6: 8 BMS
 SG_ VoltageCell9_F6 : 0|16@1+ (0.001,0) [0|65.535] "V" Vector__XXX
 SG_ VoltageCell10_F6 : 16|16@1+ (0.001,0) [0|65.535] "V" Vector__XXX
 SG_ VoltageCell11_F6 : 32|16@1+ (0.001,0) [0|65.535] "V" Vector__XXX
 SG_ VoltageCell12_F6 : 48|16@1+ (0.001,0) [0|65.535] "V" Vector__XXX

BO_ 2364575990 HVES1D1_F6: 8 BMS
 SG_ PackCurrentlvl_F6 : 48|16@1- (0.05,-1600) [0|1676.75] "A" Vector__XXX
 SG_ PackVoltagelvl_F6 : 32|16@1+ (0.05,0) [0|655.35] "V" Vector__XXX

BO_ 2365523702 SOC_F6: 8 BMS
 SG_ SoC_F6 : 0|16@1+ (1,0) [0|120] "%" Vector__XXX

BO_ 2566849782 BSVS2_F6: 8 BMS
 SG_ VoltageCell5_F6 : 0|16@1+ (0.001,0) [0|65.535] "V" Vector__XXX
 SG_ VoltageCell6_F6 : 16|16@1+ (0.001,0) [0|65.535] "V" Vector__XXX
 SG_ VoltageCell7_F6 : 32|16@1+ (0.001,0) [0|65.535] "V" Vector__XXX
 SG_ VoltageCell8_F6 : 48|16@1+ (0.001,0) [0|65.535] "V" Vector__XXX

BO_ 2566850294 BSVS4_F6: 8 BMS
 SG_ VoltageCell13_F6 : 0|16@1+ (0.001,0) [0|65.535] "V" Vector__XXX
 SG_ VoltageCell14_F6 : 16|16@1+ (0.001,0) [0|65.535] "V" Vector__XXX

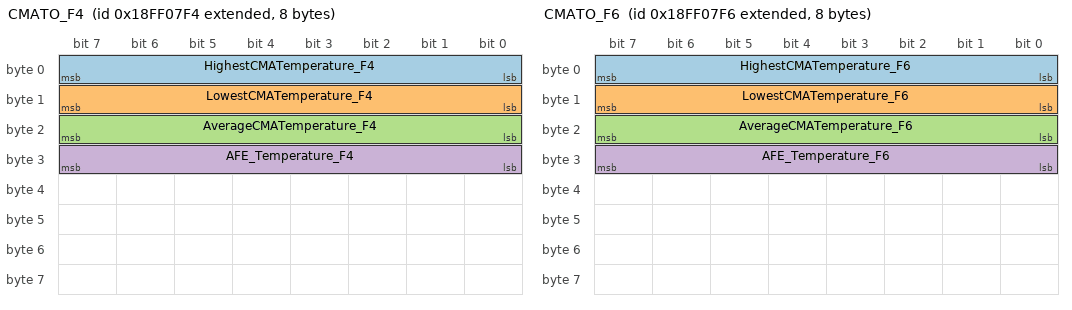
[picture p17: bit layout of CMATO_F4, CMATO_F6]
BO_ 2566850548 CMATO_F4: 8 BMS
 SG_ HighestCMATemperature_F4 : 0|8@1- (1,-40) [-40|210] "C" Vector__XXX
 SG_ LowestCMATemperature_F4 : 8|8@1- (1,-40) [-40|210] "C" Vector__XXX
 SG_ AverageCMATemperature_F4 : 16|8@1- (1,-40) [-40|210] "C" Vector__XXX
 SG_ AFE_Temperature_F4 : 24|8@1- (1,-40) [-40|210] "C" Vector__XXX

BO_ 2566850550 CMATO_F6: 8 BMS
 SG_ HighestCMATemperature_F6 : 0|8@1- (1,-40) [-40|210] "C" Vector__XXX
 SG_ LowestCMATemperature_F6 : 8|8@1- (1,-40) [-40|210] "C" Vector__XXX
 SG_ AverageCMATemperature_F6 : 16|8@1- (1,-40) [-40|210] "C" Vector__XXX
 SG_ AFE_Temperature_F6 : 24|8@1- (1,-40) [-40|210] "C" Vector__XXX

BO_ 2566850804 STATUS_F4: 8 BMS
 SG_ CommMode_F4 : 0|1@1+ (1,0) [0|1] "" Vector__XXX
 SG_ DischargeMode_F4 : 1|1@1+ (1,0) [0|1] "" Vector__XXX
 SG_ ChargeMode_F4 : 2|1@1+ (1,0) [0|1] "" Vector__XXX
 SG_ BSDCMDMode_F4 : 3|1@1+ (1,0) [0|1] "" Vector__XXX
 SG_ ReadyStatus_F4 : 8|1@1+ (1,0) [0|1] "" Vector__XXX
 SG_ NormalStatus_F4 : 9|1@1+ (1,0) [0|1] "" Vector__XXX
 SG_ FinishStatus_F4 : 10|1@1+ (1,0) [0|1] "" Vector__XXX
 SG_ ProtectStatus_F4 : 11|1@1+ (1,0) [0|1] "" Vector__XXX
 SG_ LowVoltageProtect_F4 : 16|1@1+ (1,0) [0|1] "" Vector__XXX
 SG_ TemperatureProtect_F4 : 17|1@1+ (1,0) [0|1] "" Vector__XXX
 SG_ CurrentProtect_F4 : 18|1@1+ (1,0) [0|1] "" Vector__XXX
 SG_ ZeroCurrentProtect_F4 : 19|1@1+ (1,0) [0|1] "" Vector__XXX
 SG_ OverVoltageProtect_F4 : 20|1@1+ (1,0) [0|1] "" Vector__XXX
 SG_ MaintenProtect_F4 : 21|1@1+ (1,0) [0|1] "" Vector__XXX
 SG_ BalanceProtect_F4 : 22|1@1+ (1,0) [0|1] "" Vector__XXX
 SG_ ChargerNotMatchProtect_F4 : 23|1@1+ (1,0) [0|1] "" Vector__XXX
 SG_ NoCanMsgEnableProtect_F4 : 24|1@1+ (1,0) [0|1] "" Vector__XXX
 SG_ ContactorIssueProtect_F4 : 25|1@1+ (1,0) [0|1] "" Vector__XXX
 SG_ EStopProtect_F4 : 26|1@1+ (1,0) [0|1] "" Vector__XXX
 SG_ StartVoltProtect_F4 : 27|1@1+ (1,0) [0|1] "" Vector__XXX
 SG_ BMSAddrChangedProtect_F4 : 30|1@1+ (1,0) [0|1] "" Vector__XXX
 SG_ PermanentFaultProtect_F4 : 31|1@1+ (1,0) [0|1] "" Vector__XXX
 SG_ LowVoltageAlarm_F4 : 32|1@1+ (1,0) [0|1] "" Vector__XXX
 SG_ TemperatureAlarm_F4 : 33|1@1+ (1,0) [0|1] "" Vector__XXX
 SG_ CurrentAlarm_F4 : 34|1@1+ (1,0) [0|1] "" Vector__XXX
 SG_ ZeroCurrentAlarm_F4 : 35|1@1+ (1,0) [0|1] "" Vector__XXX
 SG_ OverVoltAlarm_F4 : 36|1@1+ (1,0) [0|1] "" Vector__XXX
 SG_ MaintenaceAlarm_F4 : 37|1@1+ (1,0) [0|1] "" Vector__XXX
 SG_ BalanaceAlarm_F4 : 38|1@1+ (1,0) [0|1] "" Vector__XXX
 SG_ ChargerNotMatchAlarm_F4 : 39|1@1+ (1,0) [0|1] "" Vector__XXX
 SG_ CanMsgAlarm_F4 : 40|1@1+ (1,0) [0|1] "" Vector__XXX
 SG_ ContactorAlarm_F4 : 41|1@1+ (1,0) [0|1] "" Vector__XXX
 SG_ EstopAlarm_F4 : 42|1@1+ (1,0) [0|1] "" Vector__XXX
 SG_ StartVoltAlarm_F4 : 43|1@1+ (1,0) [0|1] "" Vector__XXX
 SG_ BMSMultipleAddressFault_F4 : 48|8@1+ (1,0) [0|255] "" Vector__XXX
 SG_ BSDCFGMODE_F4 : 4|1@1+ (1,0) [0|1] "" Vector__XXX
 SG_ AFECommAlarm_F4 : 44|1@1+ (1,0) [0|1] "" Vector__XXX
 SG_ BusVoltageMatchAlarm_F4 : 45|1@1+ (1,0) [0|1] "" Vector__XXX
 SG_ ChargerStatu_F4 : 56|8@1+ (1,0) [0|255] "" Vector__XXX

BO_ 2566850806 STATUS_F6: 8 BMS
 SG_ CommMode_F6 : 0|1@1+ (1,0) [0|1] "" Vector__XXX
 SG_ DischargeMode_F6 : 1|1@1+ (1,0) [0|1] "" Vector__XXX
 SG_ ChargeMode_F6 : 2|1@1+ (1,0) [0|1] "" Vector__XXX
 SG_ BSDCMDMode_F6 : 3|1@1+ (1,0) [0|1] "" Vector__XXX
 SG_ ReadyStatus_F6 : 8|1@1+ (1,0) [0|1] "" Vector__XXX
 SG_ NormalStatus_F6 : 9|1@1+ (1,0) [0|1] "" Vector__XXX
 SG_ FinishStatus_F6 : 10|1@1+ (1,0) [0|1] "" Vector__XXX
 SG_ ProtectStatus_F6 : 11|1@1+ (1,0) [0|1] "" Vector__XXX
 SG_ LowVoltageProtect_F6 : 16|1@1+ (1,0) [0|1] "" Vector__XXX
 SG_ TemperatureProtect_F6 : 17|1@1+ (1,0) [0|1] "" Vector__XXX
 SG_ CurrentProtect_F6 : 18|1@1+ (1,0) [0|1] "" Vector__XXX
 SG_ ZeroCurrentProtect_F6 : 19|1@1+ (1,0) [0|1] "" Vector__XXX
 SG_ OverVoltageProtect_F6 : 20|1@1+ (1,0) [0|1] "" Vector__XXX
 SG_ MaintenProtect_F6 : 21|1@1+ (1,0) [0|1] "" Vector__XXX
 SG_ BalanceProtect_F6 : 22|1@1+ (1,0) [0|1] "" Vector__XXX
 SG_ ChargerNotMatchProtect_F6 : 23|1@1+ (1,0) [0|1] "" Vector__XXX
 SG_ NoCanMsgEnableProtect_F6 : 24|1@1+ (1,0) [0|1] "" Vector__XXX
 SG_ ContactorIssueProtect_F6 : 25|1@1+ (1,0) [0|1] "" Vector__XXX
 SG_ EStopProtect_F6 : 26|1@1+ (1,0) [0|1] "" Vector__XXX
 SG_ StartVoltProtect_F6 : 27|1@1+ (1,0) [0|1] "" Vector__XXX
 SG_ BMSAddrChangedProtect_F6 : 30|1@1+ (1,0) [0|1] "" Vector__XXX
 SG_ PermanentFaultProtect_F6 : 31|1@1+ (1,0) [0|1] "" Vector__XXX
 SG_ LowVoltageAlarm_F6 : 32|1@1+ (1,0) [0|1] "" Vector__XXX
 SG_ TemperatureAlarm_F6 : 33|1@1+ (1,0) [0|1] "" Vector__XXX
 SG_ CurrentAlarm_F6 : 34|1@1+ (1,0) [0|1] "" Vector__XXX
 SG_ ZeroCurrentAlarm_F6 : 35|1@1+ (1,0) [0|1] "" Vector__XXX
 SG_ OverVoltAlarm_F6 : 36|1@1+ (1,0) [0|1] "" Vector__XXX
 SG_ MaintenaceAlarm_F6 : 37|1@1+ (1,0) [0|1] "" Vector__XXX
 SG_ BalanaceAlarm_F6 : 38|1@1+ (1,0) [0|1] "" Vector__XXX
 SG_ ChargerNotMatchAlarm_F6 : 39|1@1+ (1,0) [0|1] "" Vector__XXX
 SG_ CanMsgAlarm_F6 : 40|1@1+ (1,0) [0|1] "" Vector__XXX
 SG_ ContactorAlarm_F6 : 41|1@1+ (1,0) [0|1] "" Vector__XXX
 SG_ EstopAlarm_F6 : 42|1@1+ (1,0) [0|1] "" Vector__XXX
 SG_ StartVoltAlarm_F6 : 43|1@1+ (1,0) [0|1] "" Vector__XXX
 SG_ BMSMultipleAddressFault_F6 : 48|8@1+ (1,0) [0|255] "" Vector__XXX
 SG_ BSDCFGMODE_F6 : 4|1@1+ (1,0) [0|1] "" Vector__XXX
 SG_ ChargerStatu_F6 : 56|8@1+ (1,0) [0|255] "" Vector__XXX

BO_ 2566861044 Version_F4: 8 BMS
 SG_ PCBAVersionDate_F4 : 0|24@1+ (1,0) [0|20990000] "" Vector__XXX
 SG_ SchVersionDate_F4 : 24|24@1+ (1,0) [0|16777200] "" Vector__XXX
 SG_ SoftwareVersion_F4 : 48|16@1+ (1,0) [0|65536] "" Vector__XXX

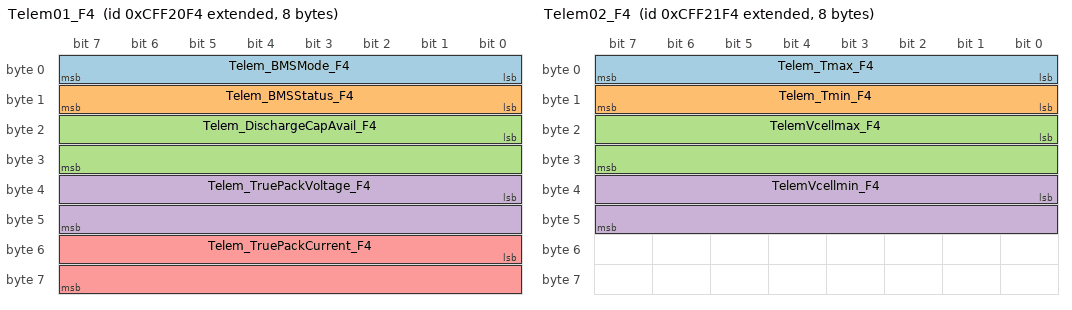
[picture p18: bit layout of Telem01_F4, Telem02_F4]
BO_ 2365530356 Telem01_F4: 8 BMS
 SG_ Telem_BMSMode_F4 : 0|8@1+ (1,0) [0|255] "" Vector__XXX
 SG_ Telem_BMSStatus_F4 : 8|8@1+ (1,0) [0|255] "" Vector__XXX
 SG_ Telem_DischargeCapAvail_F4 : 16|16@1+ (0.01,0) [0|655.35] "Ah" Vector__XXX
 SG_ Telem_TruePackVoltage_F4 : 32|16@1+ (0.001,0) [0|65.535] "V" Vector__XXX
 SG_ Telem_TruePackCurrent_F4 : 48|16@1+ (0.05,-1600) [-1600|1676.75] "A" Vector__XXX

BO_ 2365530612 Telem02_F4: 8 BMS
 SG_ Telem_Tmax_F4 : 0|8@1+ (1,-40) [-40|210] "C" Vector__XXX
 SG_ Telem_Tmin_F4 : 8|8@1+ (1,-40) [-40|210] "C" Vector__XXX
 SG_ TelemVcellmax_F4 : 16|16@1+ (0.001,0) [0|65.535] "V" Vector__XXX
 SG_ TelemVcellmin_F4 : 32|16@1+ (0.001,0) [0|65.535] "V" Vector__XXX

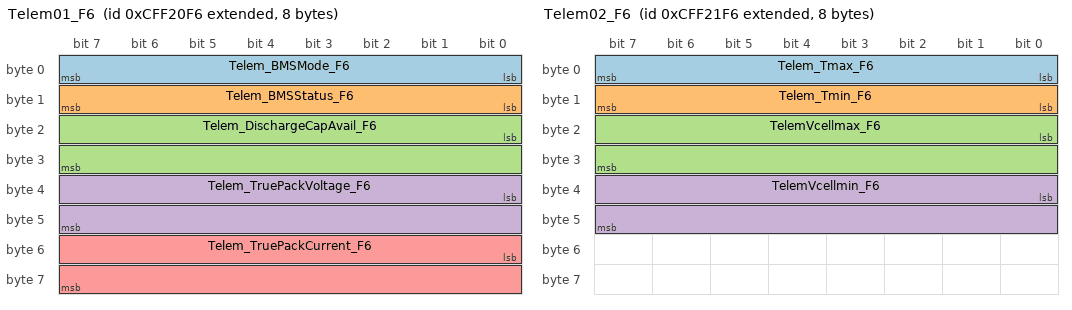
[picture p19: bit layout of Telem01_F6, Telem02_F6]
BO_ 2365530358 Telem01_F6: 8 BMS
 SG_ Telem_BMSMode_F6 : 0|8@1+ (1,0) [0|255] "" Vector__XXX
 SG_ Telem_BMSStatus_F6 : 8|8@1+ (1,0) [0|255] "" Vector__XXX
 SG_ Telem_DischargeCapAvail_F6 : 16|16@1+ (0.01,0) [0|655.35] "Ah" Vector__XXX
 SG_ Telem_TruePackVoltage_F6 : 32|16@1+ (0.001,0) [0|65.535] "V" Vector__XXX
 SG_ Telem_TruePackCurrent_F6 : 48|16@1+ (0.05,-1600) [-1600|1676.75] "A" Vector__XXX

BO_ 2365530614 Telem02_F6: 8 BMS
 SG_ Telem_Tmax_F6 : 0|8@1+ (1,-40) [-40|210] "C" Vector__XXX
 SG_ Telem_Tmin_F6 : 8|8@1+ (1,-40) [-40|210] "C" Vector__XXX
 SG_ TelemVcellmax_F6 : 16|16@1+ (0.001,0) [0|65.535] "V" Vector__XXX
 SG_ TelemVcellmin_F6 : 32|16@1+ (0.001,0) [0|65.535] "V" Vector__XXX

BO_ 2566861046 Version_F6: 8 BMS
 SG_ PCBAVersionDate_04 : 0|24@1+ (1,0) [0|20990000] "" Vector__XXX
 SG_ SchVersionDate_04 : 24|24@1+ (1,0) [0|16777200] "" Vector__XXX
 SG_ SoftwareVersion_04 : 48|16@1+ (1,0) [0|65536] "" Vector__XXX

CM_ BO_ 2364607219 "HVES 1 Data 8 (electrical data)";
CM_ SG_ 2364607219 AvgCellV_F3 "The average cell voltage in the High Voltage Energy Storage 1 pack (or system).";
CM_ SG_ 2364607219 LowestCellVModuleNum_F3 "Identifies the location of the module containing the HVES1 Lowest Cell Voltage (SPN 5923).";
CM_ SG_ 2364607219 HighestCellVModuleNum_F3 "Identifies the location of the module containing the HVES1 Highest Cell Voltage (SPN 5922).";
CM_ BO_ 2364577523 "HVES 1 Status 1";
CM_ SG_ 2364577523 CellBalancingActive_F3 "Indicates whether or not the cells in the High Voltage Energy Storage 1 pack (or system) are currently being balanced.

00 = Cell balancing is not active
01 = Cell balancing is active
10 = Error
11 = Not Available";
CM_ SG_ 2364577523 CellBalanceStatus_F3 "Indicates whether or not the cells in the High Voltage Energy Storage 1 pack (or system) are balanced.

00 = Cells are balanced
01 = Cells are unbalanced
10 = Error
11 = Not Available";
CM_ SG_ 2364577523 HVBusContactorStNEG_F3 "Position of the High Voltage Energy Storage 1 pack (or system) negative side bus contactor.  When this contactor is closed, the negative side of HVES1 is connected to the negative side of the high-voltage bus.  If a system controls the positive, ...";
CM_ SG_ 2364577523 HVBusContactorStPOS_F3 "Position of the High Voltage Energy Storage 1 pack (or system) positive side bus contactor.  When this contactor is closed, the positive side of HVES1 is connected to the positive side of the high-voltage bus.  In systems where all contactors are ...";
CM_ BO_ 2364577267 "HVES 1 Data 6 (external or interface data)";
CM_ SG_ 2364577267 BusVoltage_F3 "The voltage level of the high voltage bus, as measured by the High Voltage Energy Storage 1 pack (or system) on the bus side (not the battery side) of its contactors.";
CM_ BO_ 2364576755 "HVES 1 Data 4 (electrical data) ";
CM_ SG_ 2364576755 ChargeCapacity_01 "The amount of unused electrical charge storage in the High Voltage Energy Storage 1 pack (or system) that is available to be filled by charging, i.e. �how much empty space is remaining in the tank�.  See HVES1 Charge Energy Capacity (SPN 8206) for ...";
CM_ SG_ 2364576755 DischargeCapacity_01 "The amount of stored electrical charge in the High Voltage Energy Storage 1 pack (or system) that is available for use by the hybrid system, i.e. �how full is the tank�.  See HVES1 Discharge Energy Capacity (SPN 8205) for kilowatt-hours (kWh).";
CM_ BO_ 2350641993 "HVES 1 Control 1 (Control commands to be sent to HVES 1)";
CM_ SG_ 2350641993 HVBusConnectCmd_cF3 "Command to connect the High Voltage Energy Storage 1 pack (or system) to the high-voltage bus.  The emergency contactor closure request may be used in situations where one or more faults in the hybrid powertrain prevent normal operation, but the ...";
CM_ BO_ 2365522419 "Broadcasts individual thermal measurements.";
CM_ SG_ 2365522419 Temperature1_01 "Temperature (Thermistor) 1";
CM_ SG_ 2365522419 Temperature2_01 "Temperature (Thermistor) 2";
CM_ SG_ 2365522419 Temperature3_01 "Temperature (Thermistor) 3";
CM_ SG_ 2365522419 Temperature4_01 "Temperature (Thermistor) 4";
CM_ SG_ 2365522419 Temperature5_01 "Temperature (Thermistor) 5";
CM_ SG_ 2365522419 Temperature6_01 "Temperature (Thermistor) 6";
CM_ SG_ 2365522419 Temperature7_01 "Temperature (Thermistor) 7";
CM_ BO_ 2365522675 "Broadcasts individual thermal measurements.";
CM_ SG_ 2365522675 Temperature8_F3 "Temperature (Thermistor) 8";
CM_ SG_ 2365522675 Temperature9_F3 "Temperature (Thermistor) 9";
CM_ SG_ 2365522675 Temperature10_F3 "Temperature (Thermistor) 10";
CM_ SG_ 2365522675 Temperature11_F3 "Temperature (Thermistor) 11";
CM_ SG_ 2365522675 Temperature12_F3 "Temperature (Thermistor) 12";
CM_ SG_ 2365522675 Temperature13_F3 "Temperature (Thermistor) 13";
CM_ SG_ 2365522675 Temperature14_F3 "Temperature (Thermistor) 14";
CM_ BO_ 2566849523 "Broadcasts individual cma voltage measurements.";
CM_ SG_ 2566849523 VoltageCell1_F3 "Voltage (Cell) 1";
CM_ SG_ 2566849523 VoltageCell2_F3 "Voltage (Cell) 2";
CM_ SG_ 2566849523 VoltageCell3_F3 "Voltage (Cell) 3";
CM_ SG_ 2566849523 VoltageCell4_F3 "Voltage (Cell) 4";
CM_ BO_ 2566850035 "Broadcasts individual cma voltage measurements.";
CM_ SG_ 2566850035 VoltageCell9_F3 "Voltage (Cell) 9";
CM_ SG_ 2566850035 VoltageCell10_F3 "Voltage (Cell) 10";
CM_ SG_ 2566850035 VoltageCell11_F3 "Voltage (Cell) 11";
CM_ SG_ 2566850035 VoltageCell12_F3 "Voltage (Cell) 12";
CM_ BO_ 2364575987 "HVES 1 Data 1";
CM_ SG_ 2364575987 PackCurrentlvl_F3 "The current in or out of the High Voltage Energy Storage 1 pack (or system).  This parameter should be synchronized with SPN 5919 (HVES1 Voltage Level) such that a realized power value can be calculated.  This parameter is defined from the high ...";
CM_ SG_ 2364575987 PackVoltagelvl_F3 "The voltage level of the High Voltage Energy Storage 1 pack (or system).  This parameter should be synchronized with SPN 5920 (HVES1 Current) such that a realized power value can be calculated.  If the HVES component physically contains the ...";
CM_ BO_ 2365523699 "State of Charge Status";
CM_ SG_ 2365523699 SoC_F3 "State of charge from 0 to 120%";
CM_ BO_ 2566849779 "Broadcasts individual cma voltage measurements";
CM_ SG_ 2566849779 VoltageCell5_F3 "Voltage (Cell) 5";
CM_ SG_ 2566849779 VoltageCell6_F3 "Voltage (Cell) 6";
CM_ SG_ 2566849779 VoltageCell7_F3 "Voltage (Cell) 7";
CM_ SG_ 2566849779 VoltageCell8_F3 "Voltage (Cell) 8";
CM_ BO_ 2566850291 "Broadcasts individual cma voltage measurements.";
CM_ SG_ 2566850291 VoltageCell13_F3 "Voltage (Cell) 13";
CM_ SG_ 2566850291 VoltageCell14_F3 "Voltage (Cell) 14";
CM_ BO_ 2364607221 "HVES 1 Data 8 (electrical data)";
CM_ SG_ 2364607221 AvgCellV_F5 "The average cell voltage in the High Voltage Energy Storage 1 pack (or system).";
CM_ SG_ 2364607221 LowestCellVModuleNum_F5 "Identifies the location of the module containing the HVES1 Lowest Cell Voltage (SPN 5923).";
CM_ SG_ 2364607221 HighestCellVModuleNum_F5 "Identifies the location of the module containing the HVES1 Highest Cell Voltage (SPN 5922).";
CM_ BO_ 2364577525 "HVES 1 Status 1";
CM_ SG_ 2364577525 CellBalancingActive_F5 "Indicates whether or not the cells in the High Voltage Energy Storage 1 pack (or system) are currently being balanced.

00 = Cell balancing is not active
01 = Cell balancing is active
10 = Error
11 = Not Available ";
CM_ SG_ 2364577525 CellBalanceStatus_F5 "Indicates whether or not the cells in the High Voltage Energy Storage 1 pack (or system) are balanced.

00 = Cells are balanced
01 = Cells are unbalanced
10 = Error
11 = Not Available ";
CM_ SG_ 2364577525 HVBusContactorStNEG_F5 "Position of the High Voltage Energy Storage 1 pack (or system) negative side bus contactor. When this contactor is closed, the negative side of HVES1 is connected to the negative side of the high-voltage bus. If a system controls the positive, ... ";
CM_ SG_ 2364577525 HVBusContactorStPOS_F5 "Position of the High Voltage Energy Storage 1 pack (or system) positive side bus contactor. When this contactor is closed, the positive side of HVES1 is connected to the positive side of the high-voltage bus. In systems where all contactors are ... ";
CM_ BO_ 2364577269 "HVES 1 Data 6 (external or interface data)";
CM_ SG_ 2364577269 BusVoltage_F5 "The voltage level of the high voltage bus, as measured by the High Voltage Energy Storage 1 pack (or system) on the bus side (not the battery side) of its contactors. ";
CM_ BO_ 2364576757 "HVES 1 Data 4 (electrical data) ";
CM_ SG_ 2364576757 ChargeCapacity_F5 "The amount of unused electrical charge storage in the High Voltage Energy Storage 1 pack (or system) that is available to be filled by charging, i.e. �how much empty space is remaining in the tank�. See HVES1 Charge Energy Capacity (SPN 8206) for ... ";
CM_ SG_ 2364576757 DischargeCapacity_F5 "The amount of stored electrical charge in the High Voltage Energy Storage 1 pack (or system) that is available for use by the hybrid system, i.e. �how full is the tank�.  See HVES1 Discharge Energy Capacity (SPN 8205) for kilowatt-hours (kWh).";
CM_ BO_ 2365522421 "Broadcasts individual thermal measurements.";
CM_ SG_ 2365522421 Temperature1_F5 "Temperature (Thermistor) 1";
CM_ SG_ 2365522421 Temperature2_F5 "Temperature (Thermistor) 2";
CM_ SG_ 2365522421 Temperature3_F5 "Temperature (Thermistor) 3";
CM_ SG_ 2365522421 Temperature4_F5 "Temperature (Thermistor) 4";
CM_ SG_ 2365522421 Temperature5_F5 "Temperature (Thermistor) 5";
CM_ SG_ 2365522421 Temperature6_F5 "Temperature (Thermistor) 6";
CM_ SG_ 2365522421 Temperature7_F5 "Temperature (Thermistor) 7";
CM_ BO_ 2365522677 "Broadcasts individual thermal measurements.";
CM_ SG_ 2365522677 Temperature8_F5 "Temperature (Thermistor) 8";
CM_ SG_ 2365522677 Temperature9_F5 "Temperature (Thermistor) 9";
CM_ SG_ 2365522677 Temperature10_F5 "Temperature (Thermistor) 10";
CM_ SG_ 2365522677 Temperature11_F5 "Temperature (Thermistor) 11";
CM_ SG_ 2365522677 Temperature12_F5 "Temperature (Thermistor) 12";
CM_ SG_ 2365522677 Temperature13_F5 "Temperature (Thermistor) 13";
CM_ SG_ 2365522677 Temperature14_F5 "Temperature (Thermistor) 14";
CM_ BO_ 2566849525 "Broadcasts individual cma voltage measurements.";
CM_ SG_ 2566849525 VoltageCell1_F5 "Voltage (Cell) 1";
CM_ SG_ 2566849525 VoltageCell2_F5 "Voltage (Cell) 2";
CM_ SG_ 2566849525 VoltageCell3_F5 "Voltage (Cell) 3";
CM_ SG_ 2566849525 VoltageCell4_F5 "Voltage (Cell) 4";
CM_ BO_ 2566850037 "Broadcasts individual cma voltage measurements.";
CM_ SG_ 2566850037 VoltageCell9_F5 "Voltage (Cell) 9";
CM_ SG_ 2566850037 VoltageCell10_F5 "Voltage (Cell) 10";
CM_ SG_ 2566850037 VoltageCell11_F5 "Voltage (Cell) 11";
CM_ SG_ 2566850037 VoltageCell12_F5 "Voltage (Cell) 12";
CM_ BO_ 2364575989 "HVES 1 Data 1";
CM_ SG_ 2364575989 PackCurrentlvl_F5 "The current in or out of the High Voltage Energy Storage 1 pack (or system). This parameter should be synchronized with SPN 5919 (HVES1 Voltage Level) such that a realized power value can be calculated. This parameter is defined from the high ... ";
CM_ SG_ 2364575989 PackVoltagelvl_F5 "The voltage level of the High Voltage Energy Storage 1 pack (or system).  This parameter should be synchronized with SPN 5920 (HVES1 Current) such that a realized power value can be calculated.  If the HVES component physically contains the ...";
CM_ BO_ 2365523701 "State of Charge Status";
CM_ SG_ 2365523701 SoC_F5 "State of charge from 0 to 120% ";
CM_ BO_ 2566849781 "Broadcasts individual cma voltage measurements";
CM_ SG_ 2566849781 VoltageCell5_F5 "Voltage (Cell) 5";
CM_ SG_ 2566849781 VoltageCell6_F5 "Voltage (Cell) 6";
CM_ SG_ 2566849781 VoltageCell7_F5 "Voltage (Cell) 7";
CM_ SG_ 2566849781 VoltageCell8_F5 "Voltage (Cell) 8";
CM_ BO_ 2566850293 "Broadcasts individual cma voltage measurements.";
CM_ SG_ 2566850293 VoltageCell13_F5 "Voltage (Cell) 13 ";
CM_ SG_ 2566850293 VoltageCell14_F5 "Voltage (Cell) 14";
CM_ BO_ 2566850547 "CMA Information";
CM_ SG_ 2566850547 HighestCMATemperature_F3 "Highest CMA Temperature";
CM_ SG_ 2566850547 LowestCMATemperature_F3 "Lowest CMA Temperature";
CM_ SG_ 2566850547 AverageCMATemperature_F3 "Average CMA Temperature";
CM_ BO_ 2566850549 "CMA information";
CM_ SG_ 2566850549 HighestCMATemperature_F5 "Highest CMA Temperature";
CM_ SG_ 2566850549 LowestCMATemperature_F5 "Lowest CMA Temperature";
CM_ SG_ 2566850549 AverageCMATemperature_F5 "Average CMA Temperature";
CM_ BO_ 2566850803 "General alarm/fault status";
CM_ SG_ 2566850803 CommMode_F3 "Standby Mode
Discharge Mode
Charge Mode";
CM_ SG_ 2566850803 DischargeMode_F3 "Ready to Operate
Normal Operating State
Read to Operate (Fully Charged)
BMS in a protected state";
CM_ SG_ 2566850803 ChargeMode_F3 "Fault: Low Voltage Protection
Fault: Temperature Protection
Fault: Current Protection
Contactor Issue
Fault: Over Voltage Protection
Fault: Balance Protection
Charger not capable of charging.";
CM_ BO_ 2566850805 "Gerneral alarm/fault status";
CM_ SG_ 2566850805 CommMode_F5 "Standby Mode
Discharge Mode
Charge Mode";
CM_ SG_ 2566850805 DischargeMode_F5 "Ready to Operate
Normal Operating State
Read to Operate (Fully Charged)
BMS in a protected state";
CM_ SG_ 2566850805 ChargeMode_F5 "Fault: Low Voltage Protection
Fault: Temperature Protection
Fault: Current Protection
Contactor Issue
Fault: Over Voltage Protection
Fault: Balance Protection
Charger not capable of charging";
CM_ BO_ 2566861043 "BMS PCBA Details";
CM_ BO_ 2365530355 "Telemetry Message Set 01 from BMS1";
CM_ SG_ 2365530355 Telem_BMSMode_F3 "1=COMMUNICATION
2=DISCHARGE
3=CHARGE";
CM_ SG_ 2365530355 Telem_BMSStatus_F3 "0=NORMAL
1=ALARM or FAULT active";
CM_ SG_ 2365530355 Telem_DischargeCapAvail_F3 "Estimated Discharge Capacity Available";
CM_ SG_ 2365530355 Telem_TruePackVoltage_F3 "Sum of each individual cell voltage from AFE.";
CM_ SG_ 2365530355 Telem_TruePackCurrent_F3 "Measured Current";
CM_ BO_ 2365530611 "Telemetry Message Set 02 from BMS1";
CM_ SG_ 2365530611 Telem_Tmax_F3 "Highest measured internal temperature";
CM_ SG_ 2365530611 Telem_Tmin_F3 "Lowest measured internal temperature";
CM_ SG_ 2365530611 TelemVcellmax_F3 "Highest Cell Voltage";
CM_ SG_ 2365530611 TelemVcellmin_F3 "Lowest Cell Voltage";
CM_ BO_ 2365530357 "Telemetry Message Set 01 from BMS2";
CM_ SG_ 2365530357 Telem_BMSMode_F5 "1=COMMUNICATION
2=DISCHARGE
3=CHARGE";
CM_ SG_ 2365530357 Telem_BMSStatus_F5 "0=NORMAL
1=ALARM or FAULT active";
CM_ SG_ 2365530357 Telem_DischargeCapAvail_F5 "Estimated Discharge Capacity Available";
CM_ SG_ 2365530357 Telem_TruePackVoltage_F5 "Sum of each individual cell voltage from the BMS.";
CM_ SG_ 2365530357 Telem_TruePackCurrent_F5 "Measured Current";
CM_ BO_ 2365530613 "Telemetry Message Set 02 from BMS2";
CM_ SG_ 2365530613 Telem_Tmax_F5 "Highest measured internal temperature.";
CM_ SG_ 2365530613 Telem_Tmin_F5 "Lowest measured internal temperature.";
CM_ SG_ 2365530613 TelemVcellmax_F5 "Highest Cell Voltage";
CM_ SG_ 2365530613 TelemVcellmin_F5 "Lowest Cell Voltage";
CM_ BO_ 2566861045 "BMS PCBA Details";
CM_ BO_ 2364607220 "HVES 1 Data 8 (electrical data)";
CM_ SG_ 2364607220 AvgCellV_F4 "The average cell voltage in the High Voltage Energy Storage 1 pack (or system).";
CM_ SG_ 2364607220 LowestCellVModuleNum_F4 "Identifies the location of the module containing the HVES1 Lowest Cell Voltage (SPN 5923).";
CM_ SG_ 2364607220 HighestCellVModuleNum_F4 "Identifies the location of the module containing the HVES1 Highest Cell Voltage (SPN 5922).";
CM_ BO_ 2364577524 "HVES 1 Status 1";
CM_ SG_ 2364577524 CellBalancingActive_F4 "Indicates whether or not the cells in the High Voltage Energy Storage 1 pack (or system) are currently being balanced.

00 = Cell balancing is not active
01 = Cell balancing is active
10 = Error
11 = Not Available";
CM_ SG_ 2364577524 CellBalanceStatus_F4 "Indicates whether or not the cells in the High Voltage Energy Storage 1 pack (or system) are balanced.

00 = Cells are balanced
01 = Cells are unbalanced
10 = Error
11 = Not Available";
CM_ SG_ 2364577524 HVBusContactorStNEG_F4 "Position of the High Voltage Energy Storage 1 pack (or system) negative side bus contactor.  When this contactor is closed, the negative side of HVES1 is connected to the negative side of the high-voltage bus.  If a system controls the positive, ...";
CM_ SG_ 2364577524 HVBusContactorStPOS_F4 "Position of the High Voltage Energy Storage 1 pack (or system) positive side bus contactor.  When this contactor is closed, the positive side of HVES1 is connected to the positive side of the high-voltage bus.  In systems where all contactors are ...";
CM_ BO_ 2364577268 "HVES 1 Data 6 (external or interface data)";
CM_ SG_ 2364577268 BusVoltage_F4 "The voltage level of the high voltage bus, as measured by the High Voltage Energy Storage 1 pack (or system) on the bus side (not the battery side) of its contactors.";
CM_ BO_ 2364576756 "HVES 1 Data 4 (electrical data) ";
CM_ SG_ 2364576756 ChargeCapacity_F4 "The amount of unused electrical charge storage in the High Voltage Energy Storage 1 pack (or system) that is available to be filled by charging, i.e. �how much empty space is remaining in the tank�.  See HVES1 Charge Energy Capacity (SPN 8206) for ...";
CM_ SG_ 2364576756 DischargeCapacity_F4 "The amount of stored electrical charge in the High Voltage Energy Storage 1 pack (or system) that is available for use by the hybrid system, i.e. �how full is the tank�.  See HVES1 Discharge Energy Capacity (SPN 8205) for kilowatt-hours (kWh).";
CM_ BO_ 2350642249 "HVES 1 Control 1 (Control commands to be sent to HVES 1)";
CM_ SG_ 2350642249 HVBusConnectCmd_cF4 "Command to connect the High Voltage Energy Storage 1 pack (or system) to the high-voltage bus.  The emergency contactor closure request may be used in situations where one or more faults in the hybrid powertrain prevent normal operation, but the ...";
CM_ BO_ 2365522420 "Broadcasts individual thermal measurements.";
CM_ SG_ 2365522420 Temperature1_F4 "Temperature (Thermistor) 1";
CM_ SG_ 2365522420 Temperature2_F4 "Temperature (Thermistor) 2";
CM_ SG_ 2365522420 Temperature3_F4 "Temperature (Thermistor) 3";
CM_ SG_ 2365522420 Temperature4_F4 "Temperature (Thermistor) 4";
CM_ SG_ 2365522420 Temperature5_F4 "Temperature (Thermistor) 5";
CM_ SG_ 2365522420 Temperature6_F4 "Temperature (Thermistor) 6";
CM_ SG_ 2365522420 Temperature7_F4 "Temperature (Thermistor) 7";
CM_ BO_ 2365522676 "Broadcasts individual thermal measurements.";
CM_ SG_ 2365522676 Temperature8_F4 "Temperature (Thermistor) 8";
CM_ SG_ 2365522676 Temperature9_F4 "Temperature (Thermistor) 9";
CM_ SG_ 2365522676 Temperature10_F4 "Temperature (Thermistor) 10";
CM_ SG_ 2365522676 Temperature11_F4 "Temperature (Thermistor) 11";
CM_ SG_ 2365522676 Temperature12_F4 "Temperature (Thermistor) 12";
CM_ SG_ 2365522676 Temperature13_F4 "Temperature (Thermistor) 13";
CM_ SG_ 2365522676 Temperature14_F4 "Temperature (Thermistor) 14";
CM_ BO_ 2566849524 "Broadcasts individual cma voltage measurements.";
CM_ SG_ 2566849524 VoltageCell1_F4 "Voltage (Cell) 1";
CM_ SG_ 2566849524 VoltageCell2_F4 "Voltage (Cell) 2";
CM_ SG_ 2566849524 VoltageCell3_F4 "Voltage (Cell) 3";
CM_ SG_ 2566849524 VoltageCell4_F4 "Voltage (Cell) 4";
CM_ BO_ 2566850036 "Broadcasts individual cma voltage measurements.";
CM_ SG_ 2566850036 VoltageCell9_F4 "Voltage (Cell) 9";
CM_ SG_ 2566850036 VoltageCell10_F4 "Voltage (Cell) 10";
CM_ SG_ 2566850036 VoltageCell11_F4 "Voltage (Cell) 11";
CM_ SG_ 2566850036 VoltageCell12_F4 "Voltage (Cell) 12";
CM_ BO_ 2364575988 "HVES 1 Data 1";
CM_ SG_ 2364575988 PackCurrentlvl_F4 "The current in or out of the High Voltage Energy Storage 1 pack (or system).  This parameter should be synchronized with SPN 5919 (HVES1 Voltage Level) such that a realized power value can be calculated.  This parameter is defined from the high ...";
CM_ SG_ 2364575988 PackVoltagelvl_F4 "The voltage level of the High Voltage Energy Storage 1 pack (or system).  This parameter should be synchronized with SPN 5920 (HVES1 Current) such that a realized power value can be calculated.  If the HVES component physically contains the ...";
CM_ BO_ 2365523700 "State of Charge Status";
CM_ SG_ 2365523700 SoC_F4 "State of charge from 0 to 120%";
CM_ BO_ 2566849780 "Broadcasts individual cma voltage measurements";
CM_ SG_ 2566849780 VoltageCell5_F4 "Voltage (Cell) 5";
CM_ SG_ 2566849780 VoltageCell6_F4 "Voltage (Cell) 6";
CM_ SG_ 2566849780 VoltageCell7_F4 "Voltage (Cell) 7";
CM_ SG_ 2566849780 VoltageCell8_F4 "Voltage (Cell) 8";
CM_ BO_ 2566850292 "Broadcasts individual cma voltage measurements.";
CM_ SG_ 2566850292 VoltageCell13_F4 "Voltage (Cell) 13";
CM_ SG_ 2566850292 VoltageCell14_F4 "Voltage (Cell) 14";
CM_ BO_ 2364607222 "HVES 1 Data 8 (electrical data)";
CM_ SG_ 2364607222 AvgCellV_F6 "The average cell voltage in the High Voltage Energy Storage 1 pack (or system).";
CM_ SG_ 2364607222 LowestCellVModuleNum_F6 "Identifies the location of the module containing the HVES1 Lowest Cell Voltage (SPN 5923).";
CM_ SG_ 2364607222 HighestCellVModuleNum_F6 "Identifies the location of the module containing the HVES1 Highest Cell Voltage (SPN 5922).";
CM_ BO_ 2364577526 "HVES 1 Status 1";
CM_ SG_ 2364577526 CellBalancingActive_F6 "Indicates whether or not the cells in the High Voltage Energy Storage 1 pack (or system) are currently being balanced.

00 = Cell balancing is not active
01 = Cell balancing is active
10 = Error
11 = Not Available ";
CM_ SG_ 2364577526 CellBalanceStatus_F6 "Indicates whether or not the cells in the High Voltage Energy Storage 1 pack (or system) are balanced.

00 = Cells are balanced
01 = Cells are unbalanced
10 = Error
11 = Not Available ";
CM_ SG_ 2364577526 HVBusContactorStNEG_F6 "Position of the High Voltage Energy Storage 1 pack (or system) negative side bus contactor. When this contactor is closed, the negative side of HVES1 is connected to the negative side of the high-voltage bus. If a system controls the positive, ... ";
CM_ SG_ 2364577526 HVBusContactorStPOS_F6 "Position of the High Voltage Energy Storage 1 pack (or system) positive side bus contactor. When this contactor is closed, the positive side of HVES1 is connected to the positive side of the high-voltage bus. In systems where all contactors are ... ";
CM_ BO_ 2364577270 "HVES 1 Data 6 (external or interface data)";
CM_ SG_ 2364577270 BusVoltage_F6 "The voltage level of the high voltage bus, as measured by the High Voltage Energy Storage 1 pack (or system) on the bus side (not the battery side) of its contactors. ";
CM_ BO_ 2364576758 "HVES 1 Data 4 (electrical data) ";
CM_ SG_ 2364576758 ChargeCapacity_F6 "The amount of unused electrical charge storage in the High Voltage Energy Storage 1 pack (or system) that is available to be filled by charging, i.e. �how much empty space is remaining in the tank�. See HVES1 Charge Energy Capacity (SPN 8206) for ... ";
CM_ SG_ 2364576758 DischargeCapacity_F6 "The amount of stored electrical charge in the High Voltage Energy Storage 1 pack (or system) that is available for use by the hybrid system, i.e. �how full is the tank�.  See HVES1 Discharge Energy Capacity (SPN 8205) for kilowatt-hours (kWh).";
CM_ BO_ 2365522422 "Broadcasts individual thermal measurements.";
CM_ SG_ 2365522422 Temperature1_F6 "Temperature (Thermistor) 1";
CM_ SG_ 2365522422 Temperature2_F6 "Temperature (Thermistor) 2";
CM_ SG_ 2365522422 Temperature3_F6 "Temperature (Thermistor) 3";
CM_ SG_ 2365522422 Temperature4_F6 "Temperature (Thermistor) 4";
CM_ SG_ 2365522422 Temperature5_F6 "Temperature (Thermistor) 5";
CM_ SG_ 2365522422 Temperature6_F6 "Temperature (Thermistor) 6";
CM_ SG_ 2365522422 Temperature7_F6 "Temperature (Thermistor) 7";
CM_ BO_ 2365522678 "Broadcasts individual thermal measurements.";
CM_ SG_ 2365522678 Temperature8_F6 "Temperature (Thermistor) 8";
CM_ SG_ 2365522678 Temperature9_F6 "Temperature (Thermistor) 9";
CM_ SG_ 2365522678 Temperature10_F6 "Temperature (Thermistor) 10";
CM_ SG_ 2365522678 Temperature11_F6 "Temperature (Thermistor) 11";
CM_ SG_ 2365522678 Temperature12_F6 "Temperature (Thermistor) 12";
CM_ SG_ 2365522678 Temperature13_F6 "Temperature (Thermistor) 13";
CM_ SG_ 2365522678 Temperature14_F6 "Temperature (Thermistor) 14";
CM_ BO_ 2566849526 "Broadcasts individual cma voltage measurements.";
CM_ SG_ 2566849526 VoltageCell1_F6 "Voltage (Cell) 1";
CM_ SG_ 2566849526 VoltageCell2_F6 "Voltage (Cell) 2";
CM_ SG_ 2566849526 VoltageCell3_F6 "Voltage (Cell) 3";
CM_ SG_ 2566849526 VoltageCell4_F6 "Voltage (Cell) 4";
CM_ BO_ 2566850038 "Broadcasts individual cma voltage measurements.";
CM_ SG_ 2566850038 VoltageCell9_F6 "Voltage (Cell) 9";
CM_ SG_ 2566850038 VoltageCell10_F6 "Voltage (Cell) 10";
CM_ SG_ 2566850038 VoltageCell11_F6 "Voltage (Cell) 11";
CM_ SG_ 2566850038 VoltageCell12_F6 "Voltage (Cell) 12";
CM_ BO_ 2364575990 "HVES 1 Data 1";
CM_ SG_ 2364575990 PackCurrentlvl_F6 "The current in or out of the High Voltage Energy Storage 1 pack (or system). This parameter should be synchronized with SPN 5919 (HVES1 Voltage Level) such that a realized power value can be calculated. This parameter is defined from the high ... ";
CM_ SG_ 2364575990 PackVoltagelvl_F6 "The voltage level of the High Voltage Energy Storage 1 pack (or system).  This parameter should be synchronized with SPN 5920 (HVES1 Current) such that a realized power value can be calculated.  If the HVES component physically contains the ...";
CM_ BO_ 2365523702 "State of Charge Status";
CM_ SG_ 2365523702 SoC_F6 "State of charge from 0 to 120% ";
CM_ BO_ 2566849782 "Broadcasts individual cma voltage measurements";
CM_ SG_ 2566849782 VoltageCell5_F6 "Voltage (Cell) 5";
CM_ SG_ 2566849782 VoltageCell6_F6 "Voltage (Cell) 6";
CM_ SG_ 2566849782 VoltageCell7_F6 "Voltage (Cell) 7";
CM_ SG_ 2566849782 VoltageCell8_F6 "Voltage (Cell) 8";
CM_ BO_ 2566850294 "Broadcasts individual cma voltage measurements.";
CM_ SG_ 2566850294 VoltageCell13_F6 "Voltage (Cell) 13 ";
CM_ SG_ 2566850294 VoltageCell14_F6 "Voltage (Cell) 14";
CM_ BO_ 2566850548 "CMA Information";
CM_ SG_ 2566850548 HighestCMATemperature_F4 "Highest CMA Temperature";
CM_ SG_ 2566850548 LowestCMATemperature_F4 "Lowest CMA Temperature";
CM_ SG_ 2566850548 AverageCMATemperature_F4 "Average CMA Temperature";
CM_ BO_ 2566850550 "CMA information";
CM_ SG_ 2566850550 HighestCMATemperature_F6 "Highest CMA Temperature";
CM_ SG_ 2566850550 LowestCMATemperature_F6 "Lowest CMA Temperature";
CM_ SG_ 2566850550 AverageCMATemperature_F6 "Average CMA Temperature";
CM_ BO_ 2566850804 "General alarm/fault status";
CM_ SG_ 2566850804 CommMode_F4 "Standby Mode
Discharge Mode
Charge Mode";
CM_ SG_ 2566850804 DischargeMode_F4 "Ready to Operate
Normal Operating State
Read to Operate (Fully Charged)
BMS in a protected state";
CM_ SG_ 2566850804 ChargeMode_F4 "Fault: Low Voltage Protection
Fault: Temperature Protection
Fault: Current Protection
Contactor Issue
Fault: Over Voltage Protection
Fault: Balance Protection
Charger not capable of charging.";
CM_ BO_ 2566850806 "Gerneral alarm/fault status";
CM_ SG_ 2566850806 CommMode_F6 "Standby Mode
Discharge Mode
Charge Mode";
CM_ SG_ 2566850806 DischargeMode_F6 "Ready to Operate
Normal Operating State
Read to Operate (Fully Charged)
BMS in a protected state";
CM_ SG_ 2566850806 ChargeMode_F6 "Fault: Low Voltage Protection
Fault: Temperature Protection
Fault: Current Protection
Contactor Issue
Fault: Over Voltage Protection
Fault: Balance Protection
Charger not capable of charging";
CM_ BO_ 2566861044 "BMS PCBA Details";
CM_ BO_ 2365530356 "Telemetry Message Set 01 from BMS1";
CM_ SG_ 2365530356 Telem_BMSMode_F4 "1=COMMUNICATION
2=DISCHARGE
3=CHARGE";
CM_ SG_ 2365530356 Telem_BMSStatus_F4 "0=NORMAL
1=ALARM or FAULT active";
CM_ SG_ 2365530356 Telem_DischargeCapAvail_F4 "Estimated Discharge Capacity Available";
CM_ SG_ 2365530356 Telem_TruePackVoltage_F4 "Sum of each individual cell voltage from AFE.";
CM_ SG_ 2365530356 Telem_TruePackCurrent_F4 "Measured Current";
CM_ BO_ 2365530612 "Telemetry Message Set 02 from BMS1";
CM_ SG_ 2365530612 Telem_Tmax_F4 "Highest measured internal temperature";
CM_ SG_ 2365530612 Telem_Tmin_F4 "Lowest measured internal temperature";
CM_ SG_ 2365530612 TelemVcellmax_F4 "Highest Cell Voltage";
CM_ SG_ 2365530612 TelemVcellmin_F4 "Lowest Cell Voltage";
CM_ BO_ 2365530358 "Telemetry Message Set 01 from BMS2";
CM_ SG_ 2365530358 Telem_BMSMode_F6 "1=COMMUNICATION
2=DISCHARGE
3=CHARGE";
CM_ SG_ 2365530358 Telem_BMSStatus_F6 "0=NORMAL
1=ALARM or FAULT active";
CM_ SG_ 2365530358 Telem_DischargeCapAvail_F6 "Estimated Discharge Capacity Available";
CM_ SG_ 2365530358 Telem_TruePackVoltage_F6 "Sum of each individual cell voltage from the BMS.";
CM_ SG_ 2365530358 Telem_TruePackCurrent_F6 "Measured Current";
CM_ BO_ 2365530614 "Telemetry Message Set 02 from BMS2";
CM_ SG_ 2365530614 Telem_Tmax_F6 "Highest measured internal temperature.";
CM_ SG_ 2365530614 Telem_Tmin_F6 "Lowest measured internal temperature.";
CM_ SG_ 2365530614 TelemVcellmax_F6 "Highest Cell Voltage";
CM_ SG_ 2365530614 TelemVcellmin_F6 "Lowest Cell Voltage";
CM_ BO_ 2566861046 "BMS PCBA Details";
BA_DEF_ SG_  "SigType" ENUM  "Default","Range","RangeSigned","ASCII","Discrete","Control","ReferencePGN","DTC","StringDelimiter","StringLength","StringLengthControl","MessageCounter","MessageChecksum";
BA_DEF_ SG_  "GenSigSendType" ENUM  "Cyclic","OnWrite","OnWriteWithRepetition","OnChange","OnChangeWithRepetition","IfActive","IfActiveWithRepetition","NoSigSendType";
BA_DEF_ SG_  "GenSigILSupport" ENUM  "No","Yes";
BA_DEF_ SG_  "GenSigEVName" STRING ;
BA_DEF_ SG_  "SPN" INT 0 524287;
BA_DEF_ BO_  "GenMsgILSupport" ENUM  "No","Yes";
BA_DEF_ BO_  "GenMsgDelayTime" INT 0 1000;
BA_DEF_ BO_  "GenMsgRequestable" INT 0 1;
BA_DEF_ BO_  "GenMsgSendType" ENUM  "cyclic","NotUsed","NotUsed","NotUsed","NotUsed","NotUsed","NotUsed","IfActive","noMsgSendType";
BA_DEF_ BO_  "VFrameFormat" ENUM  "StandardCAN","ExtendedCAN","reserved","J1939PG";
BA_DEF_ BO_  "GenMsgCycleTime" INT 0 3600000;
BA_DEF_DEF_  "SigType" "Default";
BA_DEF_DEF_  "GenSigSendType" "NoSigSendType";
BA_DEF_DEF_  "GenSigILSupport" "Yes";
BA_DEF_DEF_  "GenSigEVName" "Env@Nodename_@Signame";
BA_DEF_DEF_  "SPN" 0;
BA_DEF_DEF_  "GenMsgILSupport" "Yes";
BA_DEF_DEF_  "GenMsgDelayTime" 0;
BA_DEF_DEF_  "GenMsgRequestable" 1;
BA_DEF_DEF_  "GenMsgSendType" "noMsgSendType";
BA_DEF_DEF_  "VFrameFormat" "J1939PG";
BA_DEF_DEF_  "GenMsgCycleTime" 0;
BA_ "GenMsgSendType" BO_ 2364607219 0;
BA_ "GenMsgCycleTime" BO_ 2364607219 500;
BA_ "VFrameFormat" BO_ 2364607219 1;
BA_ "GenMsgRequestable" BO_ 2364607219 0;
BA_ "SigType" SG_ 2364607219 AvgCellV_F3 1;
BA_ "SPN" SG_ 2364607219 AvgCellV_F3 8240;
BA_ "SigType" SG_ 2364607219 LowestCellVModuleNum_F3 1;
BA_ "SPN" SG_ 2364607219 LowestCellVModuleNum_F3 8238;
BA_ "SigType" SG_ 2364607219 HighestCellVModuleNum_F3 1;
BA_ "SPN" SG_ 2364607219 HighestCellVModuleNum_F3 8236;
BA_ "GenMsgDelayTime" BO_ 2364577523 20;
BA_ "GenMsgSendType" BO_ 2364577523 0;
BA_ "GenMsgCycleTime" BO_ 2364577523 500;
BA_ "VFrameFormat" BO_ 2364577523 1;
BA_ "GenMsgRequestable" BO_ 2364577523 0;
BA_ "SigType" SG_ 2364577523 CellBalancingActive_F3 4;
BA_ "SPN" SG_ 2364577523 CellBalancingActive_F3 8102;
BA_ "SigType" SG_ 2364577523 CellBalanceStatus_F3 4;
BA_ "SPN" SG_ 2364577523 CellBalanceStatus_F3 8101;
BA_ "SigType" SG_ 2364577523 HVBusContactorStNEG_F3 4;
BA_ "SPN" SG_ 2364577523 HVBusContactorStNEG_F3 8092;
BA_ "SigType" SG_ 2364577523 HVBusContactorStPOS_F3 4;
BA_ "SPN" SG_ 2364577523 HVBusContactorStPOS_F3 8091;
BA_ "GenMsgSendType" BO_ 2364577267 0;
BA_ "GenMsgCycleTime" BO_ 2364577267 50;
BA_ "VFrameFormat" BO_ 2364577267 1;
BA_ "GenMsgRequestable" BO_ 2364577267 0;
BA_ "SigType" SG_ 2364577267 BusVoltage_F3 1;
BA_ "SPN" SG_ 2364577267 BusVoltage_F3 8086;
BA_ "GenMsgSendType" BO_ 2364576755 0;
BA_ "GenMsgCycleTime" BO_ 2364576755 500;
BA_ "VFrameFormat" BO_ 2364576755 1;
BA_ "GenMsgRequestable" BO_ 2364576755 0;
BA_ "SigType" SG_ 2364576755 ChargeCapacity_01 1;
BA_ "SPN" SG_ 2364576755 ChargeCapacity_01 8080;
BA_ "SigType" SG_ 2364576755 DischargeCapacity_01 1;
BA_ "SPN" SG_ 2364576755 DischargeCapacity_01 8079;
BA_ "GenMsgSendType" BO_ 2350641993 7;
BA_ "GenMsgCycleTime" BO_ 2350641993 500;
BA_ "VFrameFormat" BO_ 2350641993 1;
BA_ "GenMsgRequestable" BO_ 2350641993 0;
BA_ "SigType" SG_ 2350641993 HVBusConnectCmd_cF3 5;
BA_ "SPN" SG_ 2350641993 HVBusConnectCmd_cF3 8123;
BA_ "VFrameFormat" BO_ 2365522419 1;
BA_ "GenMsgSendType" BO_ 2365522419 0;
BA_ "GenMsgCycleTime" BO_ 2365522419 500;
BA_ "GenMsgRequestable" BO_ 2365522419 0;
BA_ "VFrameFormat" BO_ 2365522675 1;
BA_ "GenMsgSendType" BO_ 2365522675 0;
BA_ "GenMsgCycleTime" BO_ 2365522675 500;
BA_ "GenMsgRequestable" BO_ 2365522675 0;
BA_ "VFrameFormat" BO_ 2566849523 1;
BA_ "GenMsgSendType" BO_ 2566849523 0;
BA_ "GenMsgCycleTime" BO_ 2566849523 500;
BA_ "GenMsgRequestable" BO_ 2566849523 0;
BA_ "VFrameFormat" BO_ 2566850035 1;
BA_ "GenMsgSendType" BO_ 2566850035 0;
BA_ "GenMsgCycleTime" BO_ 2566850035 500;
BA_ "GenMsgRequestable" BO_ 2566850035 0;
BA_ "GenMsgSendType" BO_ 2364575987 0;
BA_ "GenMsgCycleTime" BO_ 2364575987 500;
BA_ "VFrameFormat" BO_ 2364575987 1;
BA_ "GenMsgRequestable" BO_ 2364575987 0;
BA_ "SigType" SG_ 2364575987 PackCurrentlvl_F3 1;
BA_ "SPN" SG_ 2364575987 PackCurrentlvl_F3 5920;
BA_ "SigType" SG_ 2364575987 PackVoltagelvl_F3 1;
BA_ "SPN" SG_ 2364575987 PackVoltagelvl_F3 5919;
BA_ "VFrameFormat" BO_ 2365523699 1;
BA_ "GenMsgCycleTime" BO_ 2365523699 500;
BA_ "VFrameFormat" BO_ 2566849779 1;
BA_ "GenMsgCycleTime" BO_ 2566849779 500;
BA_ "VFrameFormat" BO_ 2566850291 1;
BA_ "GenMsgCycleTime" BO_ 2566850291 500;
BA_ "VFrameFormat" BO_ 2364607221 1;
BA_ "GenMsgCycleTime" BO_ 2364607221 500;
BA_ "VFrameFormat" BO_ 2364577525 1;
BA_ "GenMsgCycleTime" BO_ 2364577525 500;
BA_ "VFrameFormat" BO_ 2364577269 1;
BA_ "GenMsgCycleTime" BO_ 2364577269 500;
BA_ "VFrameFormat" BO_ 2364576757 1;
BA_ "GenMsgCycleTime" BO_ 2364576757 500;
BA_ "VFrameFormat" BO_ 2365522421 1;
BA_ "GenMsgCycleTime" BO_ 2365522421 500;
BA_ "VFrameFormat" BO_ 2365522677 1;
BA_ "GenMsgCycleTime" BO_ 2365522677 500;
BA_ "VFrameFormat" BO_ 2566849525 1;
BA_ "GenMsgCycleTime" BO_ 2566849525 500;
BA_ "VFrameFormat" BO_ 2566850037 1;
BA_ "GenMsgCycleTime" BO_ 2566850037 500;
BA_ "VFrameFormat" BO_ 2364575989 1;
BA_ "GenMsgCycleTime" BO_ 2364575989 500;
BA_ "VFrameFormat" BO_ 2365523701 1;
BA_ "GenMsgCycleTime" BO_ 2365523701 500;
BA_ "VFrameFormat" BO_ 2566849781 1;
BA_ "GenMsgCycleTime" BO_ 2566849781 500;
BA_ "VFrameFormat" BO_ 2566850293 1;
BA_ "GenMsgCycleTime" BO_ 2566850293 500;
BA_ "VFrameFormat" BO_ 2566850547 1;
BA_ "GenMsgCycleTime" BO_ 2566850547 500;
BA_ "VFrameFormat" BO_ 2566850549 1;
BA_ "GenMsgCycleTime" BO_ 2566850549 500;
BA_ "VFrameFormat" BO_ 2566850803 1;
BA_ "GenMsgCycleTime" BO_ 2566850803 500;
BA_ "VFrameFormat" BO_ 2566850805 1;
BA_ "GenMsgCycleTime" BO_ 2566850805 500;
BA_ "VFrameFormat" BO_ 2566861043 1;
BA_ "GenMsgCycleTime" BO_ 2566861043 10000;
BA_ "VFrameFormat" BO_ 2365530355 1;
BA_ "GenMsgCycleTime" BO_ 2365530355 100;
BA_ "VFrameFormat" BO_ 2365530611 1;
BA_ "GenMsgCycleTime" BO_ 2365530611 100;
BA_ "VFrameFormat" BO_ 2365530357 1;
BA_ "GenMsgCycleTime" BO_ 2365530357 100;
BA_ "VFrameFormat" BO_ 2365530613 1;
BA_ "GenMsgCycleTime" BO_ 2365530613 100;
BA_ "VFrameFormat" BO_ 2566861045 1;
BA_ "GenMsgCycleTime" BO_ 2566861045 10000;
BA_ "GenMsgSendType" BO_ 2364607220 0;
BA_ "GenMsgCycleTime" BO_ 2364607220 500;
BA_ "VFrameFormat" BO_ 2364607220 1;
BA_ "GenMsgRequestable" BO_ 2364607220 0;
BA_ "SigType" SG_ 2364607220 AvgCellV_F4 1;
BA_ "SPN" SG_ 2364607220 AvgCellV_F4 8240;
BA_ "SigType" SG_ 2364607220 LowestCellVModuleNum_F4 1;
BA_ "SPN" SG_ 2364607220 LowestCellVModuleNum_F4 8238;
BA_ "SigType" SG_ 2364607220 HighestCellVModuleNum_F4 1;
BA_ "SPN" SG_ 2364607220 HighestCellVModuleNum_F4 8236;
BA_ "GenMsgDelayTime" BO_ 2364577524 20;
BA_ "GenMsgSendType" BO_ 2364577524 0;
BA_ "GenMsgCycleTime" BO_ 2364577524 500;
BA_ "VFrameFormat" BO_ 2364577524 1;
BA_ "GenMsgRequestable" BO_ 2364577524 0;
BA_ "SigType" SG_ 2364577524 CellBalancingActive_F4 4;
BA_ "SPN" SG_ 2364577524 CellBalancingActive_F4 8102;
BA_ "SigType" SG_ 2364577524 CellBalanceStatus_F4 4;
BA_ "SPN" SG_ 2364577524 CellBalanceStatus_F4 8101;
BA_ "SigType" SG_ 2364577524 HVBusContactorStNEG_F4 4;
BA_ "SPN" SG_ 2364577524 HVBusContactorStNEG_F4 8092;
BA_ "SigType" SG_ 2364577524 HVBusContactorStPOS_F4 4;
BA_ "SPN" SG_ 2364577524 HVBusContactorStPOS_F4 8091;
BA_ "GenMsgSendType" BO_ 2364577268 0;
BA_ "GenMsgCycleTime" BO_ 2364577268 50;
BA_ "VFrameFormat" BO_ 2364577268 1;
BA_ "GenMsgRequestable" BO_ 2364577268 0;
BA_ "SigType" SG_ 2364577268 BusVoltage_F4 1;
BA_ "SPN" SG_ 2364577268 BusVoltage_F4 8086;
BA_ "GenMsgSendType" BO_ 2364576756 0;
BA_ "GenMsgCycleTime" BO_ 2364576756 500;
BA_ "VFrameFormat" BO_ 2364576756 1;
BA_ "GenMsgRequestable" BO_ 2364576756 0;
BA_ "SigType" SG_ 2364576756 ChargeCapacity_F4 1;
BA_ "SPN" SG_ 2364576756 ChargeCapacity_F4 8080;
BA_ "SigType" SG_ 2364576756 DischargeCapacity_F4 1;
BA_ "SPN" SG_ 2364576756 DischargeCapacity_F4 8079;
BA_ "GenMsgSendType" BO_ 2350642249 7;
BA_ "GenMsgCycleTime" BO_ 2350642249 500;
BA_ "VFrameFormat" BO_ 2350642249 1;
BA_ "GenMsgRequestable" BO_ 2350642249 0;
BA_ "SigType" SG_ 2350642249 HVBusConnectCmd_cF4 5;
BA_ "SPN" SG_ 2350642249 HVBusConnectCmd_cF4 8123;
BA_ "VFrameFormat" BO_ 2365522420 1;
BA_ "GenMsgSendType" BO_ 2365522420 0;
BA_ "GenMsgCycleTime" BO_ 2365522420 500;
BA_ "GenMsgRequestable" BO_ 2365522420 0;
BA_ "VFrameFormat" BO_ 2365522676 1;
BA_ "GenMsgSendType" BO_ 2365522676 0;
BA_ "GenMsgCycleTime" BO_ 2365522676 500;
BA_ "GenMsgRequestable" BO_ 2365522676 0;
BA_ "VFrameFormat" BO_ 2566849524 1;
BA_ "GenMsgSendType" BO_ 2566849524 0;
BA_ "GenMsgCycleTime" BO_ 2566849524 500;
BA_ "GenMsgRequestable" BO_ 2566849524 0;
BA_ "VFrameFormat" BO_ 2566850036 1;
BA_ "GenMsgSendType" BO_ 2566850036 0;
BA_ "GenMsgCycleTime" BO_ 2566850036 500;
BA_ "GenMsgRequestable" BO_ 2566850036 0;
BA_ "GenMsgSendType" BO_ 2364575988 0;
BA_ "GenMsgCycleTime" BO_ 2364575988 500;
BA_ "VFrameFormat" BO_ 2364575988 1;
BA_ "GenMsgRequestable" BO_ 2364575988 0;
BA_ "SigType" SG_ 2364575988 PackCurrentlvl_F4 1;
BA_ "SPN" SG_ 2364575988 PackCurrentlvl_F4 5920;
BA_ "SigType" SG_ 2364575988 PackVoltagelvl_F4 1;
BA_ "SPN" SG_ 2364575988 PackVoltagelvl_F4 5919;
BA_ "VFrameFormat" BO_ 2365523700 1;
BA_ "GenMsgCycleTime" BO_ 2365523700 500;
BA_ "VFrameFormat" BO_ 2566849780 1;
BA_ "GenMsgCycleTime" BO_ 2566849780 500;
BA_ "VFrameFormat" BO_ 2566850292 1;
BA_ "GenMsgCycleTime" BO_ 2566850292 500;
BA_ "VFrameFormat" BO_ 2364607222 1;
BA_ "GenMsgCycleTime" BO_ 2364607222 500;
BA_ "VFrameFormat" BO_ 2364577526 1;
BA_ "GenMsgCycleTime" BO_ 2364577526 500;
BA_ "VFrameFormat" BO_ 2364577270 1;
BA_ "GenMsgCycleTime" BO_ 2364577270 500;
BA_ "VFrameFormat" BO_ 2364576758 1;
BA_ "GenMsgCycleTime" BO_ 2364576758 500;
BA_ "VFrameFormat" BO_ 2365522422 1;
BA_ "GenMsgCycleTime" BO_ 2365522422 500;
BA_ "VFrameFormat" BO_ 2365522678 1;
BA_ "GenMsgCycleTime" BO_ 2365522678 500;
BA_ "VFrameFormat" BO_ 2566849526 1;
BA_ "GenMsgCycleTime" BO_ 2566849526 500;
BA_ "VFrameFormat" BO_ 2566850038 1;
BA_ "GenMsgCycleTime" BO_ 2566850038 500;
BA_ "VFrameFormat" BO_ 2364575990 1;
BA_ "GenMsgCycleTime" BO_ 2364575990 500;
BA_ "VFrameFormat" BO_ 2365523702 1;
BA_ "GenMsgCycleTime" BO_ 2365523702 500;
BA_ "VFrameFormat" BO_ 2566849782 1;
BA_ "GenMsgCycleTime" BO_ 2566849782 500;
BA_ "VFrameFormat" BO_ 2566850294 1;
BA_ "GenMsgCycleTime" BO_ 2566850294 500;
BA_ "VFrameFormat" BO_ 2566850548 1;
BA_ "GenMsgCycleTime" BO_ 2566850548 500;
BA_ "VFrameFormat" BO_ 2566850550 1;
BA_ "GenMsgCycleTime" BO_ 2566850550 500;
BA_ "VFrameFormat" BO_ 2566850804 1;
BA_ "GenMsgCycleTime" BO_ 2566850804 500;
BA_ "VFrameFormat" BO_ 2566850806 1;
BA_ "GenMsgCycleTime" BO_ 2566850806 500;
BA_ "VFrameFormat" BO_ 2566861044 1;
BA_ "GenMsgCycleTime" BO_ 2566861044 10000;
BA_ "VFrameFormat" BO_ 2365530356 1;
BA_ "GenMsgCycleTime" BO_ 2365530356 100;
BA_ "VFrameFormat" BO_ 2365530612 1;
BA_ "GenMsgCycleTime" BO_ 2365530612 100;
BA_ "VFrameFormat" BO_ 2365530358 1;
BA_ "GenMsgCycleTime" BO_ 2365530358 100;
BA_ "VFrameFormat" BO_ 2365530614 1;
BA_ "GenMsgCycleTime" BO_ 2365530614 100;
BA_ "VFrameFormat" BO_ 2566861046 1;
BA_ "GenMsgCycleTime" BO_ 2566861046 10000;
VAL_ 2364577523 CellBalancingActive_F3 3 "Not Available" 2 "Error" 1 "Cell balancing is active" 0 "Cell balancing is not active" ;
VAL_ 2364577523 CellBalanceStatus_F3 3 "Not Available" 2 "Error" 1 "Cells are unbalanced" 0 "Cells are balanced" ;
VAL_ 2364577523 HVBusContactorStNEG_F3 3 "Not Available" 2 "Error" 1 "Contactor Closed" 0 "Contactor Open" ;
VAL_ 2364577523 HVBusContactorStPOS_F3 3 "Not Available" 2 "Error" 1 "Contactor Closed" 0 "Contactor Open" ;
VAL_ 2350641993 HVBusConnectCmd_cF3 3 "Don't care/Take no action" 2 "Emergency contactor closure request" 1 "Close Contactor" 0 "Open Contactor" ;
VAL_ 2364577524 CellBalancingActive_F4 3 "Not Available" 2 "Error" 1 "Cell balancing is active" 0 "Cell balancing is not active" ;
VAL_ 2364577524 CellBalanceStatus_F4 3 "Not Available" 2 "Error" 1 "Cells are unbalanced" 0 "Cells are balanced" ;
VAL_ 2364577524 HVBusContactorStNEG_F4 3 "Not Available" 2 "Error" 1 "Contactor Closed" 0 "Contactor Open" ;
VAL_ 2364577524 HVBusContactorStPOS_F4 3 "Not Available" 2 "Error" 1 "Contactor Closed" 0 "Contactor Open" ;
VAL_ 2350642249 HVBusConnectCmd_cF4 3 "Don't care/Take no action" 2 "Emergency contactor closure request" 1 "Close Contactor" 0 "Open Contactor" ;
